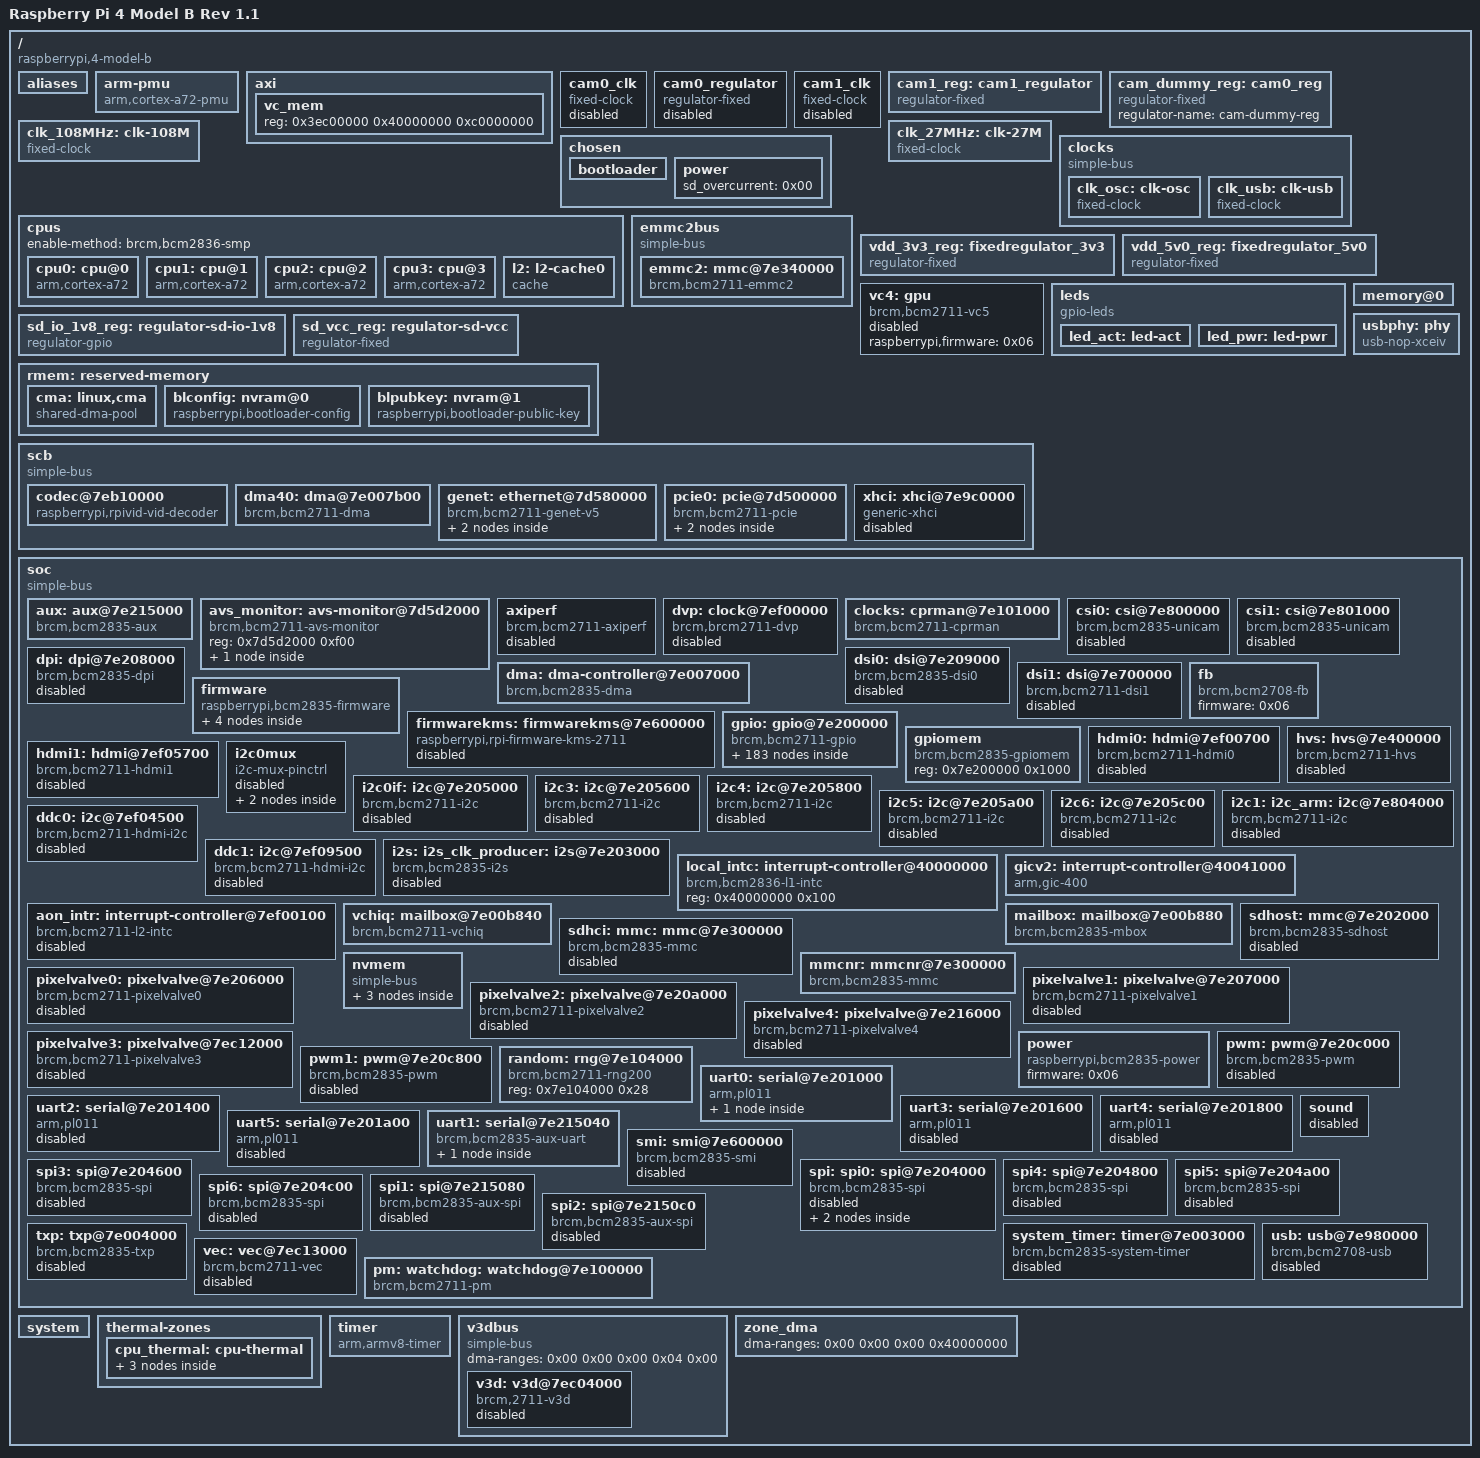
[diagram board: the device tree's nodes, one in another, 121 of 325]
/dts-v1/;

/memreserve/	0x0000000000000000 0x0000000000001000;
/ {
	#address-cells = <0x02>;
	#size-cells = <0x01>;
	compatible = "raspberrypi,4-model-b", "brcm,bcm2711";
	interrupt-parent = <0x01>;
	memreserve = <0x3b400000 0x4c00000>;
	model = "Raspberry Pi 4 Model B Rev 1.1";
	serial-number = "100000003de9072a";
	__overrides__ {
		act_led_activelow = "", "", "", "Zgpios:8";
		act_led_gpio = "", "", "", "Zgpios:4";
		act_led_trigger = "", "", "", "Zlinux,default-trigger";
		arm_freq;
		audio = "", "", "", "Tbootargs{on='snd_bcm2835.enable_headphones=1 snd_bcm2835.enable_hdmi=1',off='snd_bcm2835.enable_headphones=0 snd_bcm2835.enable_hdmi=0'}";
		axiperf = "", "", "", "Nstatus";
		bdaddr = "", "", "", "Alocal-bd-address[", "", "", "", "Afallback-bd-address?=0", "", "", "", "Blocal-bd-address[", "", "", "", "Bfallback-bd-address?=0";
		cache_line_size;
		cam0-led;
		cam0-led-ctrl;
		cam0-pwdn;
		cam0-pwdn-ctrl;
		cam0_reg = "", "", "", "Rstatus";
		cam0_reg_gpio = [00 00 00 52 67 70 69 6f 3a 34 00 00 00 00 52 67 70 69 6f 3a 30 3d 00 00 00 00 07];
		cam0_sync = "", "", "", "Qsync-gpios:0=", "", "", "", "\a", "", "", "Qsync-gpios:4", "", "", "", "Qsync-gpios:8=", "", "", "", "";
		cam0_sync_inverted = [00 00 00 51 73 79 6e 63 2d 67 70 69 6f 73 3a 30 3d 00 00 00 00 07 00 00 00 51 73 79 6e 63 2d 67 70 69 6f 73 3a 34 00 00 00 00 51 73 79 6e 63 2d 67 70 69 6f 73 3a 38 3d 00 00 00 00 01];
		cam1_reg = "", "", "", "Sstatus";
		cam1_reg_gpio = [00 00 00 53 67 70 69 6f 3a 34 00 00 00 00 53 67 70 69 6f 3a 30 3d 00 00 00 00 07];
		cam1_sync = "", "", "", "Psync-gpios:0=", "", "", "", "\a", "", "", "Psync-gpios:4", "", "", "", "Psync-gpios:8=", "", "", "", "";
		cam1_sync_inverted = [00 00 00 50 73 79 6e 63 2d 67 70 69 6f 73 3a 30 3d 00 00 00 00 07 00 00 00 50 73 79 6e 63 2d 67 70 69 6f 73 3a 34 00 00 00 00 50 73 79 6e 63 2d 67 70 69 6f 73 3a 38 3d 00 00 00 00 01];
		drm_fb0_vc4 = "", "", "", "Odrm-fb0=", "/gpu";
		drm_fb1_vc4 = "", "", "", "Odrm-fb1=", "/gpu";
		drm_fb2_vc4 = "", "", "", "Odrm-fb2=", "/gpu";
		eee = "", "", "", "Tbootargs{on='',off='genet.eee=N'}";
		eth_led0 = "", "", "", "@led-modes:0";
		eth_led1 = "", "", "", "@led-modes:4";
		hdmi = "", "", "", "Ustatus", "", "", "", "Vstatus";
		i2c = "", "", "", "Hstatus";
		i2c0 = "", "", "", "2status", "", "", "", "Gstatus";
		i2c0_baudrate = "", "", "", "2clock-frequency:0";
		i2c1 = "", "", "", "Hstatus";
		i2c1_baudrate = "", "", "", "Hclock-frequency:0";
		i2c_arm = "", "", "", "Hstatus";
		i2c_arm_baudrate = "", "", "", "Hclock-frequency:0";
		i2c_baudrate = "", "", "", "Hclock-frequency:0";
		i2c_vc = "", "", "", "2status", "", "", "", "Gstatus";
		i2c_vc_baudrate = "", "", "", "2clock-frequency:0";
		i2s = "", "", "", "Estatus";
		i2s_dma4 = <0x45 0x646d6173 0x3a303d00 0x2e 0x45 0x646d6173 0x3a383d00 0x2e>;
		krnbt = "", "", "", "Astatus";
		krnbt_baudrate = "", "", "", "Amax-speed:0", "", "", "", "Bmax-speed:0";
		nvmem_cust_rw = "", "", "", "Wrw?";
		nvmem_priv_rw = "", "", "", "Xrw?";
		pcie = "", "", "", ">status";
		pwr_led_activelow = "", "", "", "[gpios:8";
		pwr_led_gpio = "", "", "", "[gpios:4";
		pwr_led_trigger = "", "", "", "[linux,default-trigger";
		random = "", "", "", "Jstatus";
		sd = "", "", "", "Ystatus";
		sd_debug = "", "", "", "Kbrcm,debug";
		sd_force_pio = "", "", "", "Kbrcm,force-pio?";
		sd_overclock = "", "", "", "Kbrcm,overclock-50:0";
		sd_pio_limit = "", "", "", "Kbrcm,pio-limit:0";
		sd_poll_once = "", "", "", "Ynon-removable?";
		sdio_overclock = "", "", "", "Lbrcm,overclock-50:0", "", "", "", "Mbrcm,overclock-50:0";
		spi = "", "", "", "Fstatus";
		spi_dma4 = <0x46 0x646d6173 0x3a303d00 0x2e 0x46 0x646d6173 0x3a383d00 0x2e>;
		strict_gpiod = "", "", "", "Tbootargs=pinctrl_bcm2835.persist_gpio_outputs=n";
		uart0 = "", "", "", "Cstatus";
		uart1 = "", "", "", "Dstatus";
		watchdog = "", "", "", "Istatus";
	};
	__symbols__ {
		aliases = "/aliases";
		alt0 = "/soc/gpio@7e200000/alt0";
		aon_intr = "/soc/interrupt-controller@7ef00100";
		audio_pins = "/soc/gpio@7e200000/audio_pins";
		aux = "/soc/aux@7e215000";
		avs_monitor = "/soc/avs-monitor@7d5d2000";
		axiperf = "/soc/axiperf";
		blconfig = "/reserved-memory/nvram@0";
		blpubkey = "/reserved-memory/nvram@1";
		bt = "/soc/serial@7e201000/bluetooth";
		bt_pins = "/soc/gpio@7e200000/bt_pins";
		cam0_clk = "/cam0_clk";
		cam0_reg = "/cam_dummy_reg";
		cam0_regulator = "/cam0_regulator";
		cam1_clk = "/cam1_clk";
		cam1_reg = "/cam1_regulator";
		cam_dummy_reg = "/cam_dummy_reg";
		chosen = "/chosen";
		clk_108MHz = "/clk-108M";
		clk_27MHz = "/clk-27M";
		clk_osc = "/clocks/clk-osc";
		clk_usb = "/clocks/clk-usb";
		clocks = "/soc/cprman@7e101000";
		cma = "/reserved-memory/linux,cma";
		cooling_maps = "/thermal-zones/cpu-thermal/cooling-maps";
		cpu0 = "/cpus/cpu@0";
		cpu1 = "/cpus/cpu@1";
		cpu2 = "/cpus/cpu@2";
		cpu3 = "/cpus/cpu@3";
		cpu_thermal = "/thermal-zones/cpu-thermal";
		cpus = "/cpus";
		csi0 = "/soc/csi@7e800000";
		csi1 = "/soc/csi@7e801000";
		ddc0 = "/soc/i2c@7ef04500";
		ddc1 = "/soc/i2c@7ef09500";
		dma = "/soc/dma-controller@7e007000";
		dma40 = "/scb/dma@7e007b00";
		dpi = "/soc/dpi@7e208000";
		dpi_16bit_cpadhi_gpio0 = "/soc/gpio@7e200000/dpi_16bit_cpadhi_gpio0";
		dpi_16bit_cpadhi_gpio2 = "/soc/gpio@7e200000/dpi_16bit_cpadhi_gpio2";
		dpi_16bit_gpio0 = "/soc/gpio@7e200000/dpi_16bit_gpio0";
		dpi_16bit_gpio2 = "/soc/gpio@7e200000/dpi_16bit_gpio2";
		dpi_18bit_cpadhi_gpio0 = "/soc/gpio@7e200000/dpi_18bit_cpadhi_gpio0";
		dpi_18bit_cpadhi_gpio2 = "/soc/gpio@7e200000/dpi_18bit_cpadhi_gpio2";
		dpi_18bit_gpio0 = "/soc/gpio@7e200000/dpi_18bit_gpio0";
		dpi_18bit_gpio2 = "/soc/gpio@7e200000/dpi_18bit_gpio2";
		dpi_gpio0 = "/soc/gpio@7e200000/dpi-gpio0";
		dsi0 = "/soc/dsi@7e209000";
		dsi1 = "/soc/dsi@7e700000";
		dvp = "/soc/clock@7ef00000";
		emmc2 = "/emmc2bus/mmc@7e340000";
		emmc2bus = "/emmc2bus";
		emmc_gpio22 = "/soc/gpio@7e200000/emmc-gpio22";
		emmc_gpio34 = "/soc/gpio@7e200000/emmc-gpio34";
		emmc_gpio48 = "/soc/gpio@7e200000/emmc-gpio48";
		expgpio = "/soc/firmware/gpio";
		fb = "/soc/fb";
		firmware = "/soc/firmware";
		firmware_clocks = "/soc/firmware/clocks";
		firmwarekms = "/soc/firmwarekms@7e600000";
		genet = "/scb/ethernet@7d580000";
		genet_mdio = "/scb/ethernet@7d580000/mdio@e14";
		gicv2 = "/soc/interrupt-controller@40041000";
		gpclk0_gpio4 = "/soc/gpio@7e200000/gpclk0-gpio4";
		gpclk0_gpio49 = "/soc/gpio@7e200000/gpclk0-gpio49";
		gpclk1_gpio42 = "/soc/gpio@7e200000/gpclk1-gpio42";
		gpclk1_gpio44 = "/soc/gpio@7e200000/gpclk1-gpio44";
		gpclk1_gpio5 = "/soc/gpio@7e200000/gpclk1-gpio5";
		gpclk1_gpio50 = "/soc/gpio@7e200000/gpclk1-gpio50";
		gpclk2_gpio43 = "/soc/gpio@7e200000/gpclk2-gpio43";
		gpclk2_gpio51 = "/soc/gpio@7e200000/gpclk2-gpio51";
		gpclk2_gpio6 = "/soc/gpio@7e200000/gpclk2-gpio6";
		gpio = "/soc/gpio@7e200000";
		gpioout = "/soc/gpio@7e200000/gpioout";
		hdmi0 = "/soc/hdmi@7ef00700";
		hdmi1 = "/soc/hdmi@7ef05700";
		hvs = "/soc/hvs@7e400000";
		i2c0 = "/soc/i2c0mux/i2c@0";
		i2c0_gpio0 = "/soc/gpio@7e200000/i2c0if-gpio0";
		i2c0_gpio28 = "/soc/gpio@7e200000/i2c0if-gpio28";
		i2c0_gpio44 = "/soc/gpio@7e200000/i2c0if-gpio44";
		i2c0_gpio46 = "/soc/gpio@7e200000/i2c0if-gpio46";
		i2c0_pins = "/soc/gpio@7e200000/i2c0";
		i2c0if = "/soc/i2c@7e205000";
		i2c0mux = "/soc/i2c0mux";
		i2c1 = "/soc/i2c@7e804000";
		i2c1_gpio2 = "/soc/gpio@7e200000/i2c1-gpio2";
		i2c1_gpio44 = "/soc/gpio@7e200000/i2c1-gpio44";
		i2c1_gpio46 = "/soc/gpio@7e200000/i2c1-gpio46";
		i2c1_pins = "/soc/gpio@7e200000/i2c1";
		i2c3 = "/soc/i2c@7e205600";
		i2c3_gpio2 = "/soc/gpio@7e200000/i2c3-gpio2";
		i2c3_gpio4 = "/soc/gpio@7e200000/i2c3-gpio4";
		i2c3_pins = "/soc/gpio@7e200000/i2c3";
		i2c4 = "/soc/i2c@7e205800";
		i2c4_gpio6 = "/soc/gpio@7e200000/i2c4-gpio6";
		i2c4_gpio8 = "/soc/gpio@7e200000/i2c4-gpio8";
		i2c4_pins = "/soc/gpio@7e200000/i2c4";
		i2c5 = "/soc/i2c@7e205a00";
		i2c5_gpio10 = "/soc/gpio@7e200000/i2c5-gpio10";
		i2c5_gpio12 = "/soc/gpio@7e200000/i2c5-gpio12";
		i2c5_pins = "/soc/gpio@7e200000/i2c5";
		i2c6 = "/soc/i2c@7e205c00";
		i2c6_gpio0 = "/soc/gpio@7e200000/i2c6-gpio0";
		i2c6_gpio22 = "/soc/gpio@7e200000/i2c6-gpio22";
		i2c6_pins = "/soc/gpio@7e200000/i2c6";
		i2c_arm = "/soc/i2c@7e804000";
		i2c_csi_dsi = "/soc/i2c0mux/i2c@1";
		i2c_csi_dsi0 = "/soc/i2c0mux/i2c@0";
		i2c_slave_gpio8 = "/soc/gpio@7e200000/i2c-slave-gpio8";
		i2c_vc = "/soc/i2c0mux/i2c@0";
		i2s = "/soc/i2s@7e203000";
		i2s_clk_consumer = "/soc/i2s@7e203000";
		i2s_clk_producer = "/soc/i2s@7e203000";
		i2s_pins = "/soc/gpio@7e200000/i2s";
		jtag_gpio22 = "/soc/gpio@7e200000/jtag-gpio22";
		jtag_gpio48 = "/soc/gpio@7e200000/jtag-gpio48";
		l2 = "/cpus/l2-cache0";
		led_act = "/leds/led-act";
		led_pwr = "/leds/led-pwr";
		leds = "/leds";
		local_intc = "/soc/interrupt-controller@40000000";
		mailbox = "/soc/mailbox@7e00b880";
		mii_gpio28 = "/soc/gpio@7e200000/mii-gpio28";
		mii_gpio36 = "/soc/gpio@7e200000/mii-gpio36";
		minibt = "/soc/serial@7e215040/bluetooth";
		mmc = "/soc/mmc@7e300000";
		mmcnr = "/soc/mmcnr@7e300000";
		nvmem_cust = "/soc/nvmem/nvmem_cust";
		nvmem_otp = "/soc/nvmem/nvmem_otp";
		nvmem_priv = "/soc/nvmem/nvmem_priv";
		pcie0 = "/scb/pcie@7d500000";
		pcm_gpio18 = "/soc/gpio@7e200000/pcm-gpio18";
		pcm_gpio28 = "/soc/gpio@7e200000/pcm-gpio28";
		pcm_gpio50 = "/soc/gpio@7e200000/pcm-gpio50";
		phy1 = "/scb/ethernet@7d580000/mdio@e14/ethernet-phy@1";
		pixelvalve0 = "/soc/pixelvalve@7e206000";
		pixelvalve1 = "/soc/pixelvalve@7e207000";
		pixelvalve2 = "/soc/pixelvalve@7e20a000";
		pixelvalve3 = "/soc/pixelvalve@7ec12000";
		pixelvalve4 = "/soc/pixelvalve@7e216000";
		pm = "/soc/watchdog@7e100000";
		power = "/soc/power";
		pwm = "/soc/pwm@7e20c000";
		pwm0_0_gpio12 = "/soc/gpio@7e200000/pwm0-0-gpio12";
		pwm0_0_gpio18 = "/soc/gpio@7e200000/pwm0-0-gpio18";
		pwm0_0_gpio52 = "/soc/gpio@7e200000/pwm0-0-gpio52";
		pwm0_1_gpio13 = "/soc/gpio@7e200000/pwm0-1-gpio13";
		pwm0_1_gpio19 = "/soc/gpio@7e200000/pwm0-1-gpio19";
		pwm0_1_gpio45 = "/soc/gpio@7e200000/pwm0-1-gpio45";
		pwm0_1_gpio53 = "/soc/gpio@7e200000/pwm0-1-gpio53";
		pwm1 = "/soc/pwm@7e20c800";
		pwm1_0_gpio40 = "/soc/gpio@7e200000/pwm1-0-gpio40";
		pwm1_1_gpio41 = "/soc/gpio@7e200000/pwm1-1-gpio41";
		random = "/soc/rng@7e104000";
		reset = "/soc/firmware/reset";
		rgmii_gpio35 = "/soc/gpio@7e200000/rgmii-gpio35";
		rgmii_irq_gpio34 = "/soc/gpio@7e200000/rgmii-irq-gpio34";
		rgmii_irq_gpio39 = "/soc/gpio@7e200000/rgmii-irq-gpio39";
		rgmii_mdio_gpio28 = "/soc/gpio@7e200000/rgmii-mdio-gpio28";
		rgmii_mdio_gpio37 = "/soc/gpio@7e200000/rgmii-mdio-gpio37";
		rmem = "/reserved-memory";
		scb = "/scb";
		sd_io_1v8_reg = "/regulator-sd-io-1v8";
		sd_vcc_reg = "/regulator-sd-vcc";
		sdhci = "/soc/mmc@7e300000";
		sdhost = "/soc/mmc@7e202000";
		sdhost_gpio48 = "/soc/gpio@7e200000/sdhost-gpio48";
		sdio_pins = "/soc/gpio@7e200000/sdio_pins";
		smi = "/soc/smi@7e600000";
		soc = "/soc";
		sound = "/soc/sound";
		spi = "/soc/spi@7e204000";
		spi0 = "/soc/spi@7e204000";
		spi0_cs_pins = "/soc/gpio@7e200000/spi0_cs_pins";
		spi0_gpio35 = "/soc/gpio@7e200000/spi0-gpio35";
		spi0_gpio46 = "/soc/gpio@7e200000/spi0-gpio46";
		spi0_gpio7 = "/soc/gpio@7e200000/spi0-gpio7";
		spi0_pins = "/soc/gpio@7e200000/spi0_pins";
		spi1 = "/soc/spi@7e215080";
		spi1_gpio16 = "/soc/gpio@7e200000/spi1-gpio16";
		spi2 = "/soc/spi@7e2150c0";
		spi2_gpio40 = "/soc/gpio@7e200000/spi2-gpio40";
		spi2_gpio46 = "/soc/gpio@7e200000/spi2-gpio46";
		spi3 = "/soc/spi@7e204600";
		spi3_cs_pins = "/soc/gpio@7e200000/spi3_cs_pins";
		spi3_gpio0 = "/soc/gpio@7e200000/spi3-gpio0";
		spi3_pins = "/soc/gpio@7e200000/spi3_pins";
		spi4 = "/soc/spi@7e204800";
		spi4_cs_pins = "/soc/gpio@7e200000/spi4_cs_pins";
		spi4_gpio4 = "/soc/gpio@7e200000/spi4-gpio4";
		spi4_pins = "/soc/gpio@7e200000/spi4_pins";
		spi5 = "/soc/spi@7e204a00";
		spi5_cs_pins = "/soc/gpio@7e200000/spi5_cs_pins";
		spi5_gpio12 = "/soc/gpio@7e200000/spi5-gpio12";
		spi5_pins = "/soc/gpio@7e200000/spi5_pins";
		spi6 = "/soc/spi@7e204c00";
		spi6_cs_pins = "/soc/gpio@7e200000/spi6_cs_pins";
		spi6_gpio18 = "/soc/gpio@7e200000/spi6-gpio18";
		spi6_pins = "/soc/gpio@7e200000/spi6_pins";
		spidev0 = "/soc/spi@7e204000/spidev@0";
		spidev1 = "/soc/spi@7e204000/spidev@1";
		system_timer = "/soc/timer@7e003000";
		thermal = "/soc/avs-monitor@7d5d2000/thermal";
		thermal_trips = "/thermal-zones/cpu-thermal/trips";
		txp = "/soc/txp@7e004000";
		uart0 = "/soc/serial@7e201000";
		uart0_ctsrts_gpio16 = "/soc/gpio@7e200000/uart0-ctsrts-gpio16";
		uart0_ctsrts_gpio30 = "/soc/gpio@7e200000/uart0-ctsrts-gpio30";
		uart0_ctsrts_gpio38 = "/soc/gpio@7e200000/uart0-ctsrts-gpio38";
		uart0_gpio14 = "/soc/gpio@7e200000/uart0-gpio14";
		uart0_gpio32 = "/soc/gpio@7e200000/uart0-gpio32";
		uart0_gpio36 = "/soc/gpio@7e200000/uart0-gpio36";
		uart0_pins = "/soc/gpio@7e200000/uart0_pins";
		uart1 = "/soc/serial@7e215040";
		uart1_bt_pins = "/soc/gpio@7e200000/uart1_bt_pins";
		uart1_ctsrts_gpio16 = "/soc/gpio@7e200000/uart1-ctsrts-gpio16";
		uart1_ctsrts_gpio30 = "/soc/gpio@7e200000/uart1-ctsrts-gpio30";
		uart1_ctsrts_gpio42 = "/soc/gpio@7e200000/uart1-ctsrts-gpio42";
		uart1_gpio14 = "/soc/gpio@7e200000/uart1-gpio14";
		uart1_gpio32 = "/soc/gpio@7e200000/uart1-gpio32";
		uart1_gpio40 = "/soc/gpio@7e200000/uart1-gpio40";
		uart1_pins = "/soc/gpio@7e200000/uart1_pins";
		uart2 = "/soc/serial@7e201400";
		uart2_ctsrts_gpio2 = "/soc/gpio@7e200000/uart2-ctsrts-gpio2";
		uart2_gpio0 = "/soc/gpio@7e200000/uart2-gpio0";
		uart2_pins = "/soc/gpio@7e200000/uart2_pins";
		uart3 = "/soc/serial@7e201600";
		uart3_ctsrts_gpio6 = "/soc/gpio@7e200000/uart3-ctsrts-gpio6";
		uart3_gpio4 = "/soc/gpio@7e200000/uart3-gpio4";
		uart3_pins = "/soc/gpio@7e200000/uart3_pins";
		uart4 = "/soc/serial@7e201800";
		uart4_ctsrts_gpio10 = "/soc/gpio@7e200000/uart4-ctsrts-gpio10";
		uart4_gpio8 = "/soc/gpio@7e200000/uart4-gpio8";
		uart4_pins = "/soc/gpio@7e200000/uart4_pins";
		uart5 = "/soc/serial@7e201a00";
		uart5_ctsrts_gpio14 = "/soc/gpio@7e200000/uart5-ctsrts-gpio14";
		uart5_gpio12 = "/soc/gpio@7e200000/uart5-gpio12";
		uart5_pins = "/soc/gpio@7e200000/uart5_pins";
		usb = "/soc/usb@7e980000";
		usbphy = "/phy";
		v3d = "/v3dbus/v3d@7ec04000";
		v3dbus = "/v3dbus";
		vc4 = "/gpu";
		vchiq = "/soc/mailbox@7e00b840";
		vcio = "/soc/firmware/vcio";
		vdd_3v3_reg = "/fixedregulator_3v3";
		vdd_5v0_reg = "/fixedregulator_5v0";
		vec = "/soc/vec@7ec13000";
		watchdog = "/soc/watchdog@7e100000";
		xhci = "/scb/xhci@7e9c0000";
	};
	aliases: aliases {
		aux = "/soc/aux@7e215000";
		axiperf = "/soc/axiperf";
		blconfig = "/reserved-memory/nvram@0";
		blpubkey = "/reserved-memory/nvram@1";
		bluetooth = "/soc/serial@7e201000/bluetooth";
		dma = "/soc/dma-controller@7e007000";
		emmc2bus = "/emmc2bus";
		ethernet0 = "/scb/ethernet@7d580000";
		fb = "/soc/fb";
		gpio = "/soc/gpio@7e200000";
		i2c = "/soc/i2c@7e804000";
		i2c0 = "/soc/i2c0mux/i2c@0";
		i2c1 = "/soc/i2c@7e804000";
		i2c10 = "/soc/i2c0mux/i2c@1";
		i2c20 = "/soc/i2c@7ef04500";
		i2c21 = "/soc/i2c@7ef09500";
		i2c3 = "/soc/i2c@7e205600";
		i2c4 = "/soc/i2c@7e205800";
		i2c5 = "/soc/i2c@7e205a00";
		i2c6 = "/soc/i2c@7e205c00";
		i2s = "/soc/i2s@7e203000";
		leds = "/leds";
		mailbox = "/soc/mailbox@7e00b880";
		mmc = "/soc/mmc@7e300000";
		mmc0 = "/emmc2bus/mmc@7e340000";
		mmc1 = "/soc/mmcnr@7e300000";
		mmc2 = "/soc/mmc@7e202000";
		pcie0 = "/scb/pcie@7d500000";
		phandle = <0x4f>;
		random = "/soc/rng@7e104000";
		sdhost = "/soc/mmc@7e202000";
		serial0 = "/soc/serial@7e215040";
		serial1 = "/soc/serial@7e201000";
		serial2 = "/soc/serial@7e201400";
		serial3 = "/soc/serial@7e201600";
		serial4 = "/soc/serial@7e201800";
		serial5 = "/soc/serial@7e201a00";
		soc = "/soc";
		sound = "/soc/sound";
		spi0 = "/soc/spi@7e204000";
		spi1 = "/soc/spi@7e215080";
		spi2 = "/soc/spi@7e2150c0";
		spi3 = "/soc/spi@7e204600";
		spi4 = "/soc/spi@7e204800";
		spi5 = "/soc/spi@7e204a00";
		spi6 = "/soc/spi@7e204c00";
		thermal = "/soc/avs-monitor@7d5d2000/thermal";
		uart0 = "/soc/serial@7e201000";
		uart1 = "/soc/serial@7e215040";
		uart2 = "/soc/serial@7e201400";
		uart3 = "/soc/serial@7e201600";
		uart4 = "/soc/serial@7e201800";
		uart5 = "/soc/serial@7e201a00";
		usb = "/soc/usb@7e980000";
		watchdog = "/soc/watchdog@7e100000";
	};
	arm-pmu {
		compatible = "arm,cortex-a72-pmu", "arm,armv8-pmuv3", "arm,cortex-a7-pmu";
		interrupt-affinity = <0x39 0x3a 0x3b 0x3c>;
		interrupts = <0x00 0x10 0x04 0x00 0x11 0x04 0x00 0x12 0x04 0x00 0x13 0x04>;
	};
	axi {
		vc_mem {
			reg = <0x3ec00000 0x40000000 0xc0000000>;
		};
	};
	cam0_clk: cam0_clk {
		#clock-cells = <0x00>;
		compatible = "fixed-clock";
		phandle = <0xed>;
		status = "disabled";
	};
	cam0_regulator: cam0_regulator {
		compatible = "regulator-fixed";
		enable-active-high;
		phandle = <0xec>;
		regulator-name = "cam0-reg";
		status = "disabled";
	};
	cam1_clk: cam1_clk {
		#clock-cells = <0x00>;
		compatible = "fixed-clock";
		phandle = <0xeb>;
		status = "disabled";
	};
	cam1_reg: cam1_regulator {
		compatible = "regulator-fixed";
		enable-active-high;
		gpio = <0x0b 0x05 0x00>;
		phandle = <0x53>;
		regulator-name = "cam1-reg";
		status = "okay";
	};
	cam_dummy_reg: cam0_reg: cam_dummy_reg {
		compatible = "regulator-fixed";
		phandle = <0x52>;
		regulator-name = "cam-dummy-reg";
		status = "okay";
	};
	chosen: chosen {
		bootargs = "coherent_pool=1M 8250.nr_uarts=1 snd_bcm2835.enable_headphones=0 cgroup_disable=memory numa_policy=interleave bcm2708_fb.fbwidth=0 bcm2708_fb.fbheight=0 bcm2708_fb.fbswap=1 numa=fake=2 system_heap.max_order=0 iommu_dma_numa_policy=interleave smsc95xx.macaddr=DC:A6:32:42:AA:0B vc_mem.mem_base=0x3ec00000 vc_mem.mem_size=0x40000000  console=ttyAMA0,115200 kgdboc=ttyAMA0,115200 console=tty1 root=/dev/mmcblk0p2 rootfstype=ext4 rootwait";
		kaslr-seed = <0xbb563d26 0x86358a25>;
		log = <0x3ff80000 0x7ffe0>;
		os_prefix = [00];
		overlay_prefix = "overlays/";
		phandle = <0x54>;
		rng-seed = <0x9971a6e6 0x8466f46 0x72bf2d70 0xd8c0ac17 0x7b4b04eb 0x1f7221db 0xd7a8573a 0xa4d811be 0x6458ed7a 0xfa5b4908 0x6818384f 0x8538940f 0x1e90062c 0xdd7fbb8 0xb65e083f 0xc46f6a48>;
		rpi-boardrev-ext = <0x00>;
		rpi-machine-id = [32 66 35 63 31 66 37 62 34 64 32 63 32 66 62 36 35 64 65 32 37 34 38 36 38 66 31 61 35 36 35 63 0a];
		rpi-min-boot-ver = <0x00>;
		rpi-sdram-size-gbit = <0x20>;
		rpi-serial64 = "404172c63de9072a";
		stdout-path = "serial0:115200n8";
		user-warnings = [46 61 69 6c 65 64 20 74 6f 20 6f 70 65 6e 20 63 6f 6d 6d 61 6e 64 20 6c 69 6e 65 20 66 69 6c 65 20 27 63 6d 64 6c 69 6e 65 2e 74 78 74 27 0a];
		bootloader {
			boot-mode = <0x01>;
			build-timestamp = <0x6a0a134e>;
			capabilities = <0x7f>;
			partition = <0x01>;
			rsts = <0x1000>;
			tryboot = <0x00>;
			update-timestamp = <0x6a95e58c>;
			version = "224877da90f82a72dbcc9db10bcf059259f54680";
		};
		power {
			sd_overcurrent = <0x00>;
		};
	};
	clk_108MHz: clk-108M {
		#clock-cells = <0x00>;
		clock-frequency = <0x66ff300>;
		clock-output-names = "108MHz-clock";
		compatible = "fixed-clock";
		phandle = <0x2a>;
	};
	clk_27MHz: clk-27M {
		#clock-cells = <0x00>;
		clock-frequency = <0x19bfcc0>;
		clock-output-names = "27MHz-clock";
		compatible = "fixed-clock";
		phandle = <0x2f>;
	};
	clocks {
		#address-cells = <0x01>;
		#size-cells = <0x00>;
		compatible = "simple-bus";
		clk_osc: clk-osc {
			#clock-cells = <0x00>;
			clock-frequency = <0x337f980>;
			clock-output-names = "osc";
			compatible = "fixed-clock";
			phandle = <0x03>;
		};
		clk_usb: clk-usb {
			#clock-cells = <0x00>;
			clock-frequency = <0x1c9c3800>;
			clock-output-names = "otg";
			compatible = "fixed-clock";
			phandle = <0x16>;
		};
	};
	cpus: cpus {
		#address-cells = <0x01>;
		#size-cells = <0x00>;
		enable-method = "brcm,bcm2836-smp";
		phandle = <0xe6>;
		cpu0: cpu@0 {
			compatible = "arm,cortex-a72";
			cpu-release-addr = <0x00 0xd8>;
			d-cache-line-size = <0x40>;
			d-cache-sets = <0x100>;
			d-cache-size = <0x8000>;
			device_type = "cpu";
			enable-method = "spin-table";
			i-cache-line-size = <0x40>;
			i-cache-sets = <0x100>;
			i-cache-size = <0xc000>;
			next-level-cache = <0x3d>;
			phandle = <0x39>;
			reg = <0x00>;
		};
		cpu1: cpu@1 {
			compatible = "arm,cortex-a72";
			cpu-release-addr = <0x00 0xe0>;
			d-cache-line-size = <0x40>;
			d-cache-sets = <0x100>;
			d-cache-size = <0x8000>;
			device_type = "cpu";
			enable-method = "spin-table";
			i-cache-line-size = <0x40>;
			i-cache-sets = <0x100>;
			i-cache-size = <0xc000>;
			next-level-cache = <0x3d>;
			phandle = <0x3a>;
			reg = <0x01>;
		};
		cpu2: cpu@2 {
			compatible = "arm,cortex-a72";
			cpu-release-addr = <0x00 0xe8>;
			d-cache-line-size = <0x40>;
			d-cache-sets = <0x100>;
			d-cache-size = <0x8000>;
			device_type = "cpu";
			enable-method = "spin-table";
			i-cache-line-size = <0x40>;
			i-cache-sets = <0x100>;
			i-cache-size = <0xc000>;
			next-level-cache = <0x3d>;
			phandle = <0x3b>;
			reg = <0x02>;
		};
		cpu3: cpu@3 {
			compatible = "arm,cortex-a72";
			cpu-release-addr = <0x00 0xf0>;
			d-cache-line-size = <0x40>;
			d-cache-sets = <0x100>;
			d-cache-size = <0x8000>;
			device_type = "cpu";
			enable-method = "spin-table";
			i-cache-line-size = <0x40>;
			i-cache-sets = <0x100>;
			i-cache-size = <0xc000>;
			next-level-cache = <0x3d>;
			phandle = <0x3c>;
			reg = <0x03>;
		};
		l2: l2-cache0 {
			cache-level = <0x02>;
			cache-line-size = <0x40>;
			cache-sets = <0x400>;
			cache-size = <0x100000>;
			cache-unified;
			compatible = "cache";
			phandle = <0x3d>;
		};
	};
	emmc2bus: emmc2bus {
		#address-cells = <0x02>;
		#size-cells = <0x01>;
		compatible = "simple-bus";
		dma-ranges = <0x00 0xc0000000 0x00 0x00 0x40000000>;
		phandle = <0xe5>;
		ranges = <0x00 0x7e000000 0x00 0xfe000000 0x1800000>;
		emmc2: mmc@7e340000 {
			broken-cd;
			clocks = <0x08 0x33>;
			compatible = "brcm,bcm2711-emmc2";
			interrupts = <0x00 0x7e 0x04>;
			mmc-ddr-3_3v;
			phandle = <0x59>;
			reg = <0x00 0x7e340000 0x100>;
			status = "okay";
			vmmc-supply = <0x38>;
			vqmmc-supply = <0x37>;
		};
	};
	vdd_3v3_reg: fixedregulator_3v3 {
		compatible = "regulator-fixed";
		phandle = <0xef>;
		regulator-always-on;
		regulator-max-microvolt = <0x325aa0>;
		regulator-min-microvolt = <0x325aa0>;
		regulator-name = "3v3";
	};
	vdd_5v0_reg: fixedregulator_5v0 {
		compatible = "regulator-fixed";
		phandle = <0xf0>;
		regulator-always-on;
		regulator-max-microvolt = <0x4c4b40>;
		regulator-min-microvolt = <0x4c4b40>;
		regulator-name = "5v0";
	};
	vc4: gpu {
		compatible = "brcm,bcm2711-vc5";
		phandle = <0xe4>;
		raspberrypi,firmware = <0x06>;
		status = "disabled";
	};
	leds: leds {
		compatible = "gpio-leds";
		phandle = <0xee>;
		led_act: led-act {
			default-state = "off";
			gpios = <0x07 0x2a 0x00>;
			label = "ACT";
			linux,default-trigger = "mmc0";
			phandle = <0x5a>;
		};
		led_pwr: led-pwr {
			default-state = "off";
			gpios = <0x0b 0x02 0x01>;
			label = "PWR";
			linux,default-trigger = "default-on";
			phandle = <0x5b>;
		};
	};
	memory@0 {
		device_type = "memory";
		reg = <0x00 0x00 0x3b400000 0x00 0x40000000 0xbc000000>;
	};
	usbphy: phy {
		#phy-cells = <0x00>;
		compatible = "usb-nop-xceiv";
		phandle = <0x17>;
	};
	sd_io_1v8_reg: regulator-sd-io-1v8 {
		compatible = "regulator-gpio";
		gpios = <0x0b 0x04 0x00>;
		phandle = <0x37>;
		regulator-always-on;
		regulator-boot-on;
		regulator-max-microvolt = <0x325aa0>;
		regulator-min-microvolt = <0x1b7740>;
		regulator-name = "vdd-sd-io";
		regulator-settling-time-us = <0x1388>;
		states = <0x1b7740 0x01 0x325aa0 0x00>;
		status = "okay";
	};
	sd_vcc_reg: regulator-sd-vcc {
		compatible = "regulator-fixed";
		enable-active-high;
		gpio = <0x0b 0x06 0x00>;
		phandle = <0x38>;
		regulator-boot-on;
		regulator-max-microvolt = <0x325aa0>;
		regulator-min-microvolt = <0x325aa0>;
		regulator-name = "vcc-sd";
	};
	rmem: reserved-memory {
		#address-cells = <0x02>;
		#size-cells = <0x01>;
		phandle = <0x5c>;
		ranges;
		cma: linux,cma {
			alloc-ranges = <0x00 0x00 0x30000000>;
			compatible = "shared-dma-pool";
			linux,cma-default;
			phandle = <0x5d>;
			reusable;
			size = <0x4000000>;
		};
		blconfig: nvram@0 {
			#address-cells = <0x01>;
			#size-cells = <0x01>;
			compatible = "raspberrypi,bootloader-config", "nvmem-rmem";
			no-map;
			phandle = <0x5e>;
			reg = <0x00 0x3ef735c0 0x3ec>;
			status = "okay";
		};
		blpubkey: nvram@1 {
			#address-cells = <0x01>;
			#size-cells = <0x01>;
			compatible = "raspberrypi,bootloader-public-key", "nvmem-rmem";
			no-map;
			phandle = <0x5f>;
			reg = <0x00 0x3ef73380 0x200>;
			status = "okay";
		};
	};
	scb: scb {
		#address-cells = <0x02>;
		#size-cells = <0x02>;
		compatible = "simple-bus";
		dma-ranges = <0x04 0x7c000000 0x00 0xfc000000 0x00 0x3800000 0x00 0x00 0x00 0x00 0x04 0x00>;
		phandle = <0xe7>;
		ranges = <0x00 0x7c000000 0x00 0xfc000000 0x00 0x3800000 0x00 0x40000000 0x00 0xff800000 0x00 0x800000 0x06 0x00 0x06 0x00 0x00 0x80000000 0x00 0x00 0x00 0x00 0x00 0xfc000000>;
		codec@7eb10000 {
			clock-names = "hevc";
			clocks = <0x14 0x0b>;
			compatible = "raspberrypi,rpivid-vid-decoder";
			interrupts = <0x00 0x62 0x04>;
			reg = <0x00 0x7eb10000 0x00 0x1000 0x00 0x7eb00000 0x00 0x10000>;
			reg-names = "intc", "hevc";
		};
		dma40: dma@7e007b00 {
			#dma-cells = <0x01>;
			brcm,dma-channel-mask = <0x3000>;
			compatible = "brcm,bcm2711-dma";
			dma-channel-mask = <0x3000>;
			interrupt-names = "dma11", "dma12", "dma13", "dma14";
			interrupts = <0x00 0x59 0x04 0x00 0x5a 0x04 0x00 0x5b 0x04 0x00 0x5c 0x04>;
			phandle = <0x2e>;
			reg = <0x00 0x7e007b00 0x00 0x400>;
		};
		genet: ethernet@7d580000 {
			#address-cells = <0x01>;
			#size-cells = <0x01>;
			compatible = "brcm,bcm2711-genet-v5";
			interrupts = <0x00 0x9d 0x04 0x00 0x9e 0x04>;
			local-mac-address = [dc a6 32 42 aa 0b];
			phandle = <0xe8>;
			phy-handle = <0x40>;
			phy-mode = "rgmii-rxid";
			reg = <0x00 0x7d580000 0x00 0x10000>;
			status = "okay";
			genet_mdio: mdio@e14 {
				#address-cells = <0x01>;
				#size-cells = <0x00>;
				compatible = "brcm,genet-mdio-v5";
				phandle = <0xe9>;
				reg = <0xe14 0x08>;
				reg-names = "mdio";
				phy1: ethernet-phy@1 {
					led-modes = <0x00 0x08>;
					phandle = <0x40>;
					reg = <0x01>;
				};
			};
		};
		pcie0: pcie@7d500000 {
			#address-cells = <0x03>;
			#interrupt-cells = <0x01>;
			#size-cells = <0x02>;
			brcm,enable-ssc;
			compatible = "brcm,bcm2711-pcie";
			device_type = "pci";
			dma-ranges = <0x2000000 0x04 0x00 0x00 0x00 0x00 0xc0000000>;
			interrupt-map = <0x00 0x00 0x00 0x01 0x01 0x00 0x8f 0x04 0x00 0x00 0x00 0x02 0x01 0x00 0x90 0x04 0x00 0x00 0x00 0x03 0x01 0x00 0x91 0x04 0x00 0x00 0x00 0x04 0x01 0x00 0x92 0x04>;
			interrupt-map-mask = <0x00 0x00 0x00 0x07>;
			interrupt-names = "pcie", "msi";
			interrupts = <0x00 0x93 0x04 0x00 0x94 0x04>;
			msi-controller;
			msi-parent = <0x3e>;
			phandle = <0x3e>;
			ranges = <0x2000000 0x00 0x80000000 0x06 0x00 0x00 0x80000000>;
			reg = <0x00 0x7d500000 0x00 0x9310>;
			pci@0,0 {
				#address-cells = <0x03>;
				#size-cells = <0x02>;
				device_type = "pci";
				ranges;
				reg = <0x00 0x00 0x00 0x00 0x00>;
				usb@0,0 {
					reg = <0x00 0x00 0x00 0x00 0x00>;
					resets = <0x3f 0x00>;
				};
			};
		};
		xhci: xhci@7e9c0000 {
			compatible = "generic-xhci";
			interrupts = <0x00 0xb0 0x04>;
			phandle = <0xea>;
			power-domains = <0x10 0x06>;
			reg = <0x00 0x7e9c0000 0x00 0x100000>;
			status = "disabled";
		};
	};
	soc: soc {
		#address-cells = <0x01>;
		#size-cells = <0x01>;
		compatible = "simple-bus";
		dma-ranges = <0xc0000000 0x00 0x00 0x40000000 0x7c000000 0x00 0xfc000000 0x3800000>;
		phandle = <0x63>;
		ranges = <0x7e000000 0x00 0xfe000000 0x1800000 0x7c000000 0x00 0xfc000000 0x2000000 0x40000000 0x00 0xff800000 0x800000>;
		aux: aux@7e215000 {
			#clock-cells = <0x01>;
			clocks = <0x08 0x14>;
			compatible = "brcm,bcm2835-aux";
			phandle = <0x11>;
			reg = <0x7e215000 0x08>;
		};
		avs_monitor: avs-monitor@7d5d2000 {
			compatible = "brcm,bcm2711-avs-monitor", "syscon", "simple-mfd";
			phandle = <0xc7>;
			reg = <0x7d5d2000 0xf00>;
			thermal: thermal {
				#thermal-sensor-cells = <0x00>;
				compatible = "brcm,bcm2711-thermal";
				phandle = <0x02>;
			};
		};
		axiperf: axiperf {
			compatible = "brcm,bcm2711-axiperf";
			firmware = <0x06>;
			phandle = <0x4e>;
			reg = <0x7e009800 0x100 0x7ee08000 0x100>;
			status = "disabled";
		};
		dvp: clock@7ef00000 {
			#clock-cells = <0x01>;
			#reset-cells = <0x01>;
			clocks = <0x2a>;
			compatible = "brcm,brcm2711-dvp";
			phandle = <0x2b>;
			reg = <0x7ef00000 0x10>;
			status = "disabled";
		};
		clocks: cprman@7e101000 {
			#clock-cells = <0x01>;
			clocks = <0x03 0x04 0x00 0x04 0x01 0x04 0x02 0x05 0x00 0x05 0x01 0x05 0x02>;
			compatible = "brcm,bcm2711-cprman";
			firmware = <0x06>;
			phandle = <0x08>;
			reg = <0x7e101000 0x2000>;
		};
		csi0: csi@7e800000 {
			#address-cells = <0x01>;
			#clock-cells = <0x01>;
			#size-cells = <0x00>;
			clock-names = "lp", "vpu";
			clocks = <0x08 0x2d 0x14 0x04>;
			compatible = "brcm,bcm2835-unicam";
			interrupts = <0x00 0x66 0x04>;
			phandle = <0x51>;
			power-domains = <0x10 0x0c>;
			reg = <0x7e800000 0x800 0x7e802000 0x04>;
			status = "disabled";
		};
		csi1: csi@7e801000 {
			#address-cells = <0x01>;
			#clock-cells = <0x01>;
			#size-cells = <0x00>;
			brcm,num-data-lanes = <0x02>;
			clock-names = "lp", "vpu";
			clocks = <0x08 0x2e 0x14 0x04>;
			compatible = "brcm,bcm2835-unicam";
			interrupts = <0x00 0x67 0x04>;
			phandle = <0x50>;
			power-domains = <0x10 0x0d>;
			reg = <0x7e801000 0x800 0x7e802004 0x04>;
			status = "disabled";
		};
		dma: dma-controller@7e007000 {
			#dma-cells = <0x01>;
			brcm,dma-channel-mask = <0x7f5>;
			compatible = "brcm,bcm2835-dma";
			interrupt-names = "dma0", "dma1", "dma2", "dma3", "dma4", "dma5", "dma6", "dma7", "dma8", "dma9", "dma10";
			interrupts = <0x00 0x50 0x04 0x00 0x51 0x04 0x00 0x52 0x04 0x00 0x53 0x04 0x00 0x54 0x04 0x00 0x55 0x04 0x00 0x56 0x04 0x00 0x57 0x04 0x00 0x57 0x04 0x00 0x58 0x04 0x00 0x58 0x04>;
			phandle = <0x0c>;
			reg = <0x7e007000 0xb00>;
		};
		dpi: dpi@7e208000 {
			clock-names = "core", "pixel";
			clocks = <0x08 0x14 0x08 0x2c>;
			compatible = "brcm,bcm2835-dpi";
			phandle = <0xc0>;
			reg = <0x7e208000 0x8c>;
			status = "disabled";
		};
		dsi0: dsi@7e209000 {
			#address-cells = <0x01>;
			#clock-cells = <0x01>;
			#size-cells = <0x00>;
			clock-names = "phy", "escape", "pixel";
			clock-output-names = "dsi0_byte", "dsi0_ddr2", "dsi0_ddr";
			clocks = <0x08 0x22 0x08 0x2f 0x08 0x31>;
			compatible = "brcm,bcm2835-dsi0";
			interrupts = <0x00 0x64 0x04>;
			phandle = <0x04>;
			power-domains = <0x10 0x11>;
			reg = <0x7e209000 0x78>;
			status = "disabled";
		};
		dsi1: dsi@7e700000 {
			#address-cells = <0x01>;
			#clock-cells = <0x01>;
			#size-cells = <0x00>;
			clock-names = "phy", "escape", "pixel";
			clock-output-names = "dsi1_byte", "dsi1_ddr2", "dsi1_ddr";
			clocks = <0x08 0x23 0x08 0x30 0x08 0x32>;
			compatible = "brcm,bcm2711-dsi1";
			interrupts = <0x00 0x6c 0x04>;
			phandle = <0x05>;
			power-domains = <0x10 0x12>;
			reg = <0x7e700000 0x8c>;
			status = "disabled";
		};
		fb: fb {
			compatible = "brcm,bcm2708-fb";
			firmware = <0x06>;
			phandle = <0xe1>;
			status = "okay";
		};
		firmware: firmware {
			#address-cells = <0x01>;
			#size-cells = <0x01>;
			compatible = "raspberrypi,bcm2835-firmware", "simple-mfd";
			dma-ranges;
			mboxes = <0x35>;
			phandle = <0x06>;
			firmware_clocks: clocks {
				#clock-cells = <0x01>;
				compatible = "raspberrypi,firmware-clocks";
				phandle = <0x14>;
			};
			expgpio: gpio {
				#gpio-cells = <0x02>;
				compatible = "raspberrypi,firmware-gpio";
				gpio-controller;
				gpio-line-names = "BT_ON", "WL_ON", "PWR_LED_OFF", "GLOBAL_RESET", "VDD_SD_IO_SEL", "CAM_GPIO", "SD_PWR_ON", "SD_OC_N";
				phandle = <0x0b>;
				status = "okay";
			};
			reset: reset {
				#reset-cells = <0x01>;
				compatible = "raspberrypi,firmware-reset";
				phandle = <0x3f>;
			};
			vcio: vcio {
				compatible = "raspberrypi,vcio";
				phandle = <0xdf>;
			};
		};
		firmwarekms: firmwarekms@7e600000 {
			brcm,firmware = <0x06>;
			compatible = "raspberrypi,rpi-firmware-kms-2711";
			interrupts = <0x00 0x70 0x04>;
			phandle = <0xdb>;
			reg = <0x7e600000 0x100>;
			status = "disabled";
		};
		gpio: gpio@7e200000 {
			#gpio-cells = <0x02>;
			#interrupt-cells = <0x02>;
			compatible = "brcm,bcm2711-gpio";
			gpio-controller;
			gpio-line-names = "ID_SDA", "ID_SCL", "GPIO2", "GPIO3", "GPIO4", "GPIO5", "GPIO6", "GPIO7", "GPIO8", "GPIO9", "GPIO10", "GPIO11", "GPIO12", "GPIO13", "GPIO14", "GPIO15", "GPIO16", "GPIO17", "GPIO18", "GPIO19", "GPIO20", "GPIO21", "GPIO22", "GPIO23", "GPIO24", "GPIO25", "GPIO26", "GPIO27", "RGMII_MDIO", "RGMIO_MDC", "CTS0", "RTS0", "TXD0", "RXD0", "SD1_CLK", "SD1_CMD", "SD1_DATA0", "SD1_DATA1", "SD1_DATA2", "SD1_DATA3", "PWM0_MISO", "PWM1_MOSI", "STATUS_LED_G_CLK", "SPIFLASH_CE_N", "SDA0", "SCL0", "RGMII_RXCLK", "RGMII_RXCTL", "RGMII_RXD0", "RGMII_RXD1", "RGMII_RXD2", "RGMII_RXD3", "RGMII_TXCLK", "RGMII_TXCTL", "RGMII_TXD0", "RGMII_TXD1", "RGMII_TXD2", "RGMII_TXD3";
			gpio-ranges = <0x07 0x00 0x00 0x3a>;
			interrupt-controller;
			interrupts = <0x00 0x71 0x04 0x00 0x72 0x04>;
			phandle = <0x07>;
			reg = <0x7e200000 0xb4>;
			alt0: alt0 {
				brcm,function = <0x04>;
				brcm,pins = <0x04 0x05 0x07 0x08 0x09 0x0a 0x0b>;
				phandle = <0xbb>;
			};
			audio_pins: audio_pins {
				brcm,function = <0x04>;
				brcm,pins = <0x28 0x29>;
				brcm,pull = <0x00>;
				phandle = <0x36>;
			};
			bt_pins: bt_pins {
				brcm,function = <0x00>;
				brcm,pins = "-";
				brcm,pull = <0x02>;
				phandle = <0x0a>;
			};
			dpi_gpio0: dpi-gpio0 {
				brcm,function = <0x06>;
				brcm,pins = <0x00 0x01 0x02 0x03 0x04 0x05 0x06 0x07 0x08 0x09 0x0a 0x0b 0x0c 0x0d 0x0e 0x0f 0x10 0x11 0x12 0x13 0x14 0x15 0x16 0x17 0x18 0x19 0x1a 0x1b>;
				phandle = <0x66>;
			};
			dpi_16bit_cpadhi_gpio0: dpi_16bit_cpadhi_gpio0 {
				brcm,function = <0x06>;
				brcm,pins = <0x00 0x01 0x02 0x03 0x04 0x05 0x06 0x07 0x08 0x0c 0x0d 0x0e 0x0f 0x10 0x11 0x14 0x15 0x16 0x17 0x18>;
				phandle = <0xb8>;
			};
			dpi_16bit_cpadhi_gpio2: dpi_16bit_cpadhi_gpio2 {
				brcm,function = <0x06>;
				brcm,pins = <0x02 0x03 0x04 0x05 0x06 0x07 0x08 0x0c 0x0d 0x0e 0x0f 0x10 0x11 0x14 0x15 0x16 0x17 0x18>;
				phandle = <0xb9>;
			};
			dpi_16bit_gpio0: dpi_16bit_gpio0 {
				brcm,function = <0x06>;
				brcm,pins = <0x00 0x01 0x02 0x03 0x04 0x05 0x06 0x07 0x08 0x09 0x0a 0x0b 0x0c 0x0d 0x0e 0x0f 0x10 0x11 0x12 0x13>;
				phandle = <0xb6>;
			};
			dpi_16bit_gpio2: dpi_16bit_gpio2 {
				brcm,function = <0x06>;
				brcm,pins = <0x02 0x03 0x04 0x05 0x06 0x07 0x08 0x09 0x0a 0x0b 0x0c 0x0d 0x0e 0x0f 0x10 0x11 0x12 0x13>;
				phandle = <0xb7>;
			};
			dpi_18bit_cpadhi_gpio0: dpi_18bit_cpadhi_gpio0 {
				brcm,function = <0x06>;
				brcm,pins = <0x00 0x01 0x02 0x03 0x04 0x05 0x06 0x07 0x08 0x09 0x0c 0x0d 0x0e 0x0f 0x10 0x11 0x14 0x15 0x16 0x17 0x18 0x19>;
				brcm,pull = <0x00>;
				phandle = <0xb2>;
			};
			dpi_18bit_cpadhi_gpio2: dpi_18bit_cpadhi_gpio2 {
				brcm,function = <0x06>;
				brcm,pins = <0x02 0x03 0x04 0x05 0x06 0x07 0x08 0x09 0x0c 0x0d 0x0e 0x0f 0x10 0x11 0x14 0x15 0x16 0x17 0x18 0x19>;
				phandle = <0xb3>;
			};
			dpi_18bit_gpio0: dpi_18bit_gpio0 {
				brcm,function = <0x06>;
				brcm,pins = <0x00 0x01 0x02 0x03 0x04 0x05 0x06 0x07 0x08 0x09 0x0a 0x0b 0x0c 0x0d 0x0e 0x0f 0x10 0x11 0x12 0x13 0x14 0x15>;
				phandle = <0xb4>;
			};
			dpi_18bit_gpio2: dpi_18bit_gpio2 {
				brcm,function = <0x06>;
				brcm,pins = <0x02 0x03 0x04 0x05 0x06 0x07 0x08 0x09 0x0a 0x0b 0x0c 0x0d 0x0e 0x0f 0x10 0x11 0x12 0x13 0x14 0x15>;
				phandle = <0xb5>;
			};
			emmc_gpio22: emmc-gpio22 {
				brcm,function = <0x07>;
				brcm,pins = <0x16 0x17 0x18 0x19 0x1a 0x1b>;
				phandle = <0x67>;
			};
			emmc_gpio34: emmc-gpio34 {
				brcm,function = <0x07>;
				brcm,pins = <0x22 0x23 0x24 0x25 0x26 0x27>;
				brcm,pull = <0x00 0x02 0x02 0x02 0x02 0x02>;
				phandle = <0x68>;
			};
			emmc_gpio48: emmc-gpio48 {
				brcm,function = <0x07>;
				brcm,pins = <0x30 0x31 0x32 0x33 0x34 0x35>;
				phandle = <0x13>;
			};
			gpclk0_gpio4: gpclk0-gpio4 {
				brcm,function = <0x04>;
				brcm,pins = <0x04>;
				phandle = <0x69>;
			};
			gpclk0_gpio49: gpclk0-gpio49 {
				phandle = <0x86>;
				pin-gpclk {
					bias-disable;
					function = "alt1";
					pins = "gpio49";
				};
			};
			gpclk1_gpio42: gpclk1-gpio42 {
				brcm,function = <0x04>;
				brcm,pins = <0x2a>;
				phandle = <0x6b>;
			};
			gpclk1_gpio44: gpclk1-gpio44 {
				brcm,function = <0x04>;
				brcm,pins = <0x2c>;
				phandle = <0x6c>;
			};
			gpclk1_gpio5: gpclk1-gpio5 {
				brcm,function = <0x04>;
				brcm,pins = <0x05>;
				phandle = <0x6a>;
			};
			gpclk1_gpio50: gpclk1-gpio50 {
				phandle = <0x87>;
				pin-gpclk {
					bias-disable;
					function = "alt1";
					pins = "gpio50";
				};
			};
			gpclk2_gpio43: gpclk2-gpio43 {
				brcm,function = <0x04>;
				brcm,pins = <0x2b>;
				brcm,pull = <0x00>;
				phandle = <0x6e>;
			};
			gpclk2_gpio51: gpclk2-gpio51 {
				phandle = <0x88>;
				pin-gpclk {
					bias-disable;
					function = "alt1";
					pins = "gpio51";
				};
			};
			gpclk2_gpio6: gpclk2-gpio6 {
				brcm,function = <0x04>;
				brcm,pins = <0x06>;
				phandle = <0x6d>;
			};
			gpioout: gpioout {
				brcm,function = <0x01>;
				brcm,pins = <0x06>;
				phandle = <0xba>;
			};
			i2c_slave_gpio8: i2c-slave-gpio8 {
				phandle = <0x93>;
				pins-i2c-slave {
					function = "alt3";
					pins = "gpio8", "gpio9", "gpio10", "gpio11";
				};
			};
			i2c0_pins: i2c0 {
				brcm,function = <0x04>;
				brcm,pins = <0x00 0x01>;
				brcm,pull = <0x02>;
				phandle = <0xbc>;
			};
			i2c0_gpio0: i2c0if-gpio0 {
				brcm,function = <0x04>;
				brcm,pins = <0x00 0x01>;
				phandle = <0x33>;
			};
			i2c0_gpio28: i2c0if-gpio28 {
				brcm,function = <0x04>;
				brcm,pins = <0x1c 0x1d>;
				phandle = <0x6f>;
			};
			i2c0_gpio44: i2c0if-gpio44 {
				brcm,function = <0x05>;
				brcm,pins = <0x2c 0x2d>;
				phandle = <0x34>;
			};
			i2c0_gpio46: i2c0if-gpio46 {
				phandle = <0x89>;
				pin-scl {
					bias-disable;
					function = "alt0";
					pins = "gpio47";
				};
				pin-sda {
					bias-pull-up;
					function = "alt0";
					pins = "gpio46";
				};
			};
			i2c1_pins: i2c1 {
				brcm,function = <0x04>;
				brcm,pins = <0x02 0x03>;
				brcm,pull = <0x02>;
				phandle = <0x15>;
			};
			i2c1_gpio2: i2c1-gpio2 {
				brcm,function = <0x04>;
				brcm,pins = <0x02 0x03>;
				phandle = <0x70>;
			};
			i2c1_gpio44: i2c1-gpio44 {
				brcm,function = <0x06>;
				brcm,pins = <0x2c 0x2d>;
				phandle = <0x71>;
			};
			i2c1_gpio46: i2c1-gpio46 {
				phandle = <0x8a>;
				pin-scl {
					bias-disable;
					function = "alt1";
					pins = "gpio47";
				};
				pin-sda {
					bias-pull-up;
					function = "alt1";
					pins = "gpio46";
				};
			};
			i2c3_pins: i2c3 {
				brcm,function = <0x02>;
				brcm,pins = <0x04 0x05>;
				brcm,pull = <0x02>;
				phandle = <0x24>;
			};
			i2c3_gpio2: i2c3-gpio2 {
				phandle = <0x8b>;
				pin-scl {
					bias-disable;
					function = "alt5";
					pins = "gpio3";
				};
				pin-sda {
					bias-pull-up;
					function = "alt5";
					pins = "gpio2";
				};
			};
			i2c3_gpio4: i2c3-gpio4 {
				phandle = <0x8c>;
				pin-scl {
					bias-disable;
					function = "alt5";
					pins = "gpio5";
				};
				pin-sda {
					bias-pull-up;
					function = "alt5";
					pins = "gpio4";
				};
			};
			i2c4_pins: i2c4 {
				brcm,function = <0x02>;
				brcm,pins = <0x08 0x09>;
				brcm,pull = <0x02>;
				phandle = <0x25>;
			};
			i2c4_gpio6: i2c4-gpio6 {
				phandle = <0x8d>;
				pin-scl {
					bias-disable;
					function = "alt5";
					pins = "gpio7";
				};
				pin-sda {
					bias-pull-up;
					function = "alt5";
					pins = "gpio6";
				};
			};
			i2c4_gpio8: i2c4-gpio8 {
				phandle = <0x8e>;
				pin-scl {
					bias-disable;
					function = "alt5";
					pins = "gpio9";
				};
				pin-sda {
					bias-pull-up;
					function = "alt5";
					pins = "gpio8";
				};
			};
			i2c5_pins: i2c5 {
				brcm,function = <0x02>;
				brcm,pins = <0x0c 0x0d>;
				brcm,pull = <0x02>;
				phandle = <0x26>;
			};
			i2c5_gpio10: i2c5-gpio10 {
				phandle = <0x8f>;
				pin-scl {
					bias-disable;
					function = "alt5";
					pins = "gpio11";
				};
				pin-sda {
					bias-pull-up;
					function = "alt5";
					pins = "gpio10";
				};
			};
			i2c5_gpio12: i2c5-gpio12 {
				phandle = <0x90>;
				pin-scl {
					bias-disable;
					function = "alt5";
					pins = "gpio13";
				};
				pin-sda {
					bias-pull-up;
					function = "alt5";
					pins = "gpio12";
				};
			};
			i2c6_pins: i2c6 {
				brcm,function = <0x02>;
				brcm,pins = <0x16 0x17>;
				brcm,pull = <0x02>;
				phandle = <0x27>;
			};
			i2c6_gpio0: i2c6-gpio0 {
				phandle = <0x91>;
				pin-scl {
					bias-disable;
					function = "alt5";
					pins = "gpio1";
				};
				pin-sda {
					bias-pull-up;
					function = "alt5";
					pins = "gpio0";
				};
			};
			i2c6_gpio22: i2c6-gpio22 {
				phandle = <0x92>;
				pin-scl {
					bias-disable;
					function = "alt5";
					pins = "gpio23";
				};
				pin-sda {
					bias-pull-up;
					function = "alt5";
					pins = "gpio22";
				};
			};
			i2s_pins: i2s {
				brcm,function = <0x04>;
				brcm,pins = <0x12 0x13 0x14 0x15>;
				phandle = <0x0d>;
			};
			jtag_gpio22: jtag-gpio22 {
				brcm,function = <0x03>;
				brcm,pins = <0x16 0x17 0x18 0x19 0x1a 0x1b>;
				phandle = <0x72>;
			};
			jtag_gpio48: jtag-gpio48 {
				phandle = <0x94>;
				pins-jtag {
					function = "alt4";
					pins = "gpio48", "gpio49", "gpio50", "gpio51", "gpio52", "gpio53";
				};
			};
			mii_gpio28: mii-gpio28 {
				phandle = <0x95>;
				pins-mii {
					function = "alt4";
					pins = "gpio28", "gpio29", "gpio30", "gpio31";
				};
			};
			mii_gpio36: mii-gpio36 {
				phandle = <0x96>;
				pins-mii {
					function = "alt5";
					pins = "gpio36", "gpio37", "gpio38", "gpio39";
				};
			};
			pcm_gpio18: pcm-gpio18 {
				brcm,function = <0x04>;
				brcm,pins = <0x12 0x13 0x14 0x15>;
				phandle = <0x73>;
			};
			pcm_gpio28: pcm-gpio28 {
				brcm,function = <0x06>;
				brcm,pins = <0x1c 0x1d 0x1e 0x1f>;
				phandle = <0x74>;
			};
			pcm_gpio50: pcm-gpio50 {
				phandle = <0x97>;
				pins-pcm {
					function = "alt2";
					pins = "gpio50", "gpio51", "gpio52", "gpio53";
				};
			};
			pwm0_0_gpio12: pwm0-0-gpio12 {
				phandle = <0x98>;
				pin-pwm {
					bias-disable;
					function = "alt0";
					pins = "gpio12";
				};
			};
			pwm0_0_gpio18: pwm0-0-gpio18 {
				phandle = <0x99>;
				pin-pwm {
					bias-disable;
					function = "alt5";
					pins = "gpio18";
				};
			};
			pwm0_0_gpio52: pwm0-0-gpio52 {
				phandle = <0x9d>;
				pin-pwm {
					bias-disable;
					function = "alt1";
					pins = "gpio52";
				};
			};
			pwm0_1_gpio13: pwm0-1-gpio13 {
				phandle = <0x9a>;
				pin-pwm {
					bias-disable;
					function = "alt0";
					pins = "gpio13";
				};
			};
			pwm0_1_gpio19: pwm0-1-gpio19 {
				phandle = <0x9b>;
				pin-pwm {
					bias-disable;
					function = "alt5";
					pins = "gpio19";
				};
			};
			pwm0_1_gpio45: pwm0-1-gpio45 {
				phandle = <0x9c>;
				pin-pwm {
					bias-disable;
					function = "alt0";
					pins = "gpio45";
				};
			};
			pwm0_1_gpio53: pwm0-1-gpio53 {
				phandle = <0x9e>;
				pin-pwm {
					bias-disable;
					function = "alt1";
					pins = "gpio53";
				};
			};
			pwm1_0_gpio40: pwm1-0-gpio40 {
				phandle = <0x28>;
				pin-pwm {
					bias-disable;
					function = "alt0";
					pins = "gpio40";
				};
			};
			pwm1_1_gpio41: pwm1-1-gpio41 {
				phandle = <0x29>;
				pin-pwm {
					bias-disable;
					function = "alt0";
					pins = "gpio41";
				};
			};
			rgmii_gpio35: rgmii-gpio35 {
				phandle = <0x9f>;
				pin-rx-ok {
					function = "alt4";
					pins = "gpio36";
				};
				pin-start-stop {
					function = "alt4";
					pins = "gpio35";
				};
			};
			rgmii_irq_gpio34: rgmii-irq-gpio34 {
				phandle = <0xa0>;
				pin-irq {
					function = "alt5";
					pins = "gpio34";
				};
			};
			rgmii_irq_gpio39: rgmii-irq-gpio39 {
				phandle = <0xa1>;
				pin-irq {
					function = "alt4";
					pins = "gpio39";
				};
			};
			rgmii_mdio_gpio28: rgmii-mdio-gpio28 {
				phandle = <0xa2>;
				pins-mdio {
					function = "alt5";
					pins = "gpio28", "gpio29";
				};
			};
			rgmii_mdio_gpio37: rgmii-mdio-gpio37 {
				phandle = <0xa3>;
				pins-mdio {
					function = "alt4";
					pins = "gpio37", "gpio38";
				};
			};
			sdhost_gpio48: sdhost-gpio48 {
				brcm,function = <0x04>;
				brcm,pins = <0x30 0x31 0x32 0x33 0x34 0x35>;
				phandle = <0x75>;
			};
			sdio_pins: sdio_pins {
				brcm,function = <0x07>;
				brcm,pins = <0x22 0x23 0x24 0x25 0x26 0x27>;
				brcm,pull = <0x00 0x02 0x02 0x02 0x02 0x02>;
				phandle = <0x31>;
			};
			spi0_gpio35: spi0-gpio35 {
				brcm,function = <0x04>;
				brcm,pins = <0x23 0x24 0x25 0x26 0x27>;
				phandle = <0x77>;
			};
			spi0_gpio46: spi0-gpio46 {
				phandle = <0xa4>;
				pins-spi {
					function = "alt2";
					pins = "gpio46", "gpio47", "gpio48", "gpio49";
				};
			};
			spi0_gpio7: spi0-gpio7 {
				brcm,function = <0x04>;
				brcm,pins = <0x07 0x08 0x09 0x0a 0x0b>;
				phandle = <0x76>;
			};
			spi0_cs_pins: spi0_cs_pins {
				brcm,function = <0x01>;
				brcm,pins = <0x08 0x07>;
				phandle = <0x0f>;
			};
			spi0_pins: spi0_pins {
				brcm,function = <0x04>;
				brcm,pins = <0x09 0x0a 0x0b>;
				phandle = <0x0e>;
			};
			spi1_gpio16: spi1-gpio16 {
				brcm,function = <0x03>;
				brcm,pins = <0x10 0x11 0x12 0x13 0x14 0x15>;
				phandle = <0x78>;
			};
			spi2_gpio40: spi2-gpio40 {
				brcm,function = <0x03>;
				brcm,pins = <0x28 0x29 0x2a 0x2b 0x2c 0x2d>;
				phandle = <0x79>;
			};
			spi2_gpio46: spi2-gpio46 {
				phandle = <0xa5>;
				pins-spi {
					function = "alt5";
					pins = "gpio46", "gpio47", "gpio48", "gpio49", "gpio50";
				};
			};
			spi3_gpio0: spi3-gpio0 {
				phandle = <0xa6>;
				pins-spi {
					function = "alt3";
					pins = "gpio0", "gpio1", "gpio2", "gpio3";
				};
			};
			spi3_cs_pins: spi3_cs_pins {
				brcm,function = <0x01>;
				brcm,pins = <0x00 0x18>;
				phandle = <0x1d>;
			};
			spi3_pins: spi3_pins {
				brcm,function = <0x07>;
				brcm,pins = <0x01 0x02 0x03>;
				phandle = <0x1c>;
			};
			spi4_gpio4: spi4-gpio4 {
				phandle = <0xa7>;
				pins-spi {
					function = "alt3";
					pins = "gpio4", "gpio5", "gpio6", "gpio7";
				};
			};
			spi4_cs_pins: spi4_cs_pins {
				brcm,function = <0x01>;
				brcm,pins = <0x04 0x19>;
				phandle = <0x1f>;
			};
			spi4_pins: spi4_pins {
				brcm,function = <0x07>;
				brcm,pins = <0x05 0x06 0x07>;
				phandle = <0x1e>;
			};
			spi5_gpio12: spi5-gpio12 {
				phandle = <0xa8>;
				pins-spi {
					function = "alt3";
					pins = "gpio12", "gpio13", "gpio14", "gpio15";
				};
			};
			spi5_cs_pins: spi5_cs_pins {
				brcm,function = <0x01>;
				brcm,pins = <0x0c 0x1a>;
				phandle = <0x21>;
			};
			spi5_pins: spi5_pins {
				brcm,function = <0x07>;
				brcm,pins = <0x0d 0x0e 0x0f>;
				phandle = <0x20>;
			};
			spi6_gpio18: spi6-gpio18 {
				phandle = <0xa9>;
				pins-spi {
					function = "alt3";
					pins = "gpio18", "gpio19", "gpio20", "gpio21";
				};
			};
			spi6_cs_pins: spi6_cs_pins {
				brcm,function = <0x01>;
				brcm,pins = <0x12 0x1b>;
				phandle = <0x23>;
			};
			spi6_pins: spi6_pins {
				brcm,function = <0x07>;
				brcm,pins = <0x13 0x14 0x15>;
				phandle = <0x22>;
			};
			uart0_ctsrts_gpio16: uart0-ctsrts-gpio16 {
				brcm,function = <0x07>;
				brcm,pins = <0x10 0x11>;
				phandle = <0x7b>;
			};
			uart0_ctsrts_gpio30: uart0-ctsrts-gpio30 {
				brcm,function = <0x07>;
				brcm,pins = <0x1e 0x1f>;
				brcm,pull = <0x02 0x00>;
				phandle = <0x7c>;
			};
			uart0_ctsrts_gpio38: uart0-ctsrts-gpio38 {
				brcm,function = <0x06>;
				brcm,pins = <0x26 0x27>;
				phandle = <0x7f>;
			};
			uart0_gpio14: uart0-gpio14 {
				brcm,function = <0x04>;
				brcm,pins = <0x0e 0x0f>;
				phandle = <0x7a>;
			};
			uart0_gpio32: uart0-gpio32 {
				brcm,function = <0x07>;
				brcm,pins = <0x20 0x21>;
				brcm,pull = <0x00 0x02>;
				phandle = <0x7d>;
			};
			uart0_gpio36: uart0-gpio36 {
				brcm,function = <0x06>;
				brcm,pins = <0x24 0x25>;
				phandle = <0x7e>;
			};
			uart0_pins: uart0_pins {
				brcm,function = <0x07>;
				brcm,pins = <0x1e 0x1f 0x20 0x21>;
				brcm,pull = <0x02 0x00 0x00 0x02>;
				phandle = <0x09>;
			};
			uart1_ctsrts_gpio16: uart1-ctsrts-gpio16 {
				brcm,function = <0x02>;
				brcm,pins = <0x10 0x11>;
				phandle = <0x81>;
			};
			uart1_ctsrts_gpio30: uart1-ctsrts-gpio30 {
				brcm,function = <0x02>;
				brcm,pins = <0x1e 0x1f>;
				phandle = <0x83>;
			};
			uart1_ctsrts_gpio42: uart1-ctsrts-gpio42 {
				brcm,function = <0x02>;
				brcm,pins = <0x2a 0x2b>;
				phandle = <0x85>;
			};
			uart1_gpio14: uart1-gpio14 {
				brcm,function = <0x02>;
				brcm,pins = <0x0e 0x0f>;
				phandle = <0x80>;
			};
			uart1_gpio32: uart1-gpio32 {
				brcm,function = <0x02>;
				brcm,pins = <0x20 0x21>;
				phandle = <0x82>;
			};
			uart1_gpio40: uart1-gpio40 {
				brcm,function = <0x02>;
				brcm,pins = <0x28 0x29>;
				phandle = <0x84>;
			};
			uart1_bt_pins: uart1_bt_pins {
				brcm,function = <0x02>;
				brcm,pins = <0x20 0x21 0x1e 0x1f>;
				brcm,pull = <0x00 0x02 0x02 0x00>;
				phandle = <0xbd>;
			};
			uart1_pins: uart1_pins {
				brcm,function;
				brcm,pins;
				brcm,pull;
				phandle = <0x12>;
			};
			uart2_ctsrts_gpio2: uart2-ctsrts-gpio2 {
				phandle = <0xab>;
				pin-cts {
					bias-pull-up;
					function = "alt4";
					pins = "gpio2";
				};
				pin-rts {
					bias-disable;
					function = "alt4";
					pins = "gpio3";
				};
			};
			uart2_gpio0: uart2-gpio0 {
				phandle = <0xaa>;
				pin-rx {
					bias-pull-up;
					function = "alt4";
					pins = "gpio1";
				};
				pin-tx {
					bias-disable;
					function = "alt4";
					pins = "gpio0";
				};
			};
			uart2_pins: uart2_pins {
				brcm,function = <0x03>;
				brcm,pins = <0x00 0x01>;
				brcm,pull = <0x00 0x02>;
				phandle = <0x18>;
			};
			uart3_ctsrts_gpio6: uart3-ctsrts-gpio6 {
				phandle = <0xad>;
				pin-cts {
					bias-pull-up;
					function = "alt4";
					pins = "gpio6";
				};
				pin-rts {
					bias-disable;
					function = "alt4";
					pins = "gpio7";
				};
			};
			uart3_gpio4: uart3-gpio4 {
				phandle = <0xac>;
				pin-rx {
					bias-pull-up;
					function = "alt4";
					pins = "gpio5";
				};
				pin-tx {
					bias-disable;
					function = "alt4";
					pins = "gpio4";
				};
			};
			uart3_pins: uart3_pins {
				brcm,function = <0x03>;
				brcm,pins = <0x04 0x05>;
				brcm,pull = <0x00 0x02>;
				phandle = <0x19>;
			};
			uart4_ctsrts_gpio10: uart4-ctsrts-gpio10 {
				phandle = <0xaf>;
				pin-cts {
					bias-pull-up;
					function = "alt4";
					pins = "gpio10";
				};
				pin-rts {
					bias-disable;
					function = "alt4";
					pins = "gpio11";
				};
			};
			uart4_gpio8: uart4-gpio8 {
				phandle = <0xae>;
				pin-rx {
					bias-pull-up;
					function = "alt4";
					pins = "gpio9";
				};
				pin-tx {
					bias-disable;
					function = "alt4";
					pins = "gpio8";
				};
			};
			uart4_pins: uart4_pins {
				brcm,function = <0x03>;
				brcm,pins = <0x08 0x09>;
				brcm,pull = <0x00 0x02>;
				phandle = <0x1a>;
			};
			uart5_ctsrts_gpio14: uart5-ctsrts-gpio14 {
				phandle = <0xb1>;
				pin-cts {
					bias-pull-up;
					function = "alt4";
					pins = "gpio14";
				};
				pin-rts {
					bias-disable;
					function = "alt4";
					pins = "gpio15";
				};
			};
			uart5_gpio12: uart5-gpio12 {
				phandle = <0xb0>;
				pin-rx {
					bias-pull-up;
					function = "alt4";
					pins = "gpio13";
				};
				pin-tx {
					bias-disable;
					function = "alt4";
					pins = "gpio12";
				};
			};
			uart5_pins: uart5_pins {
				brcm,function = <0x03>;
				brcm,pins = <0x0c 0x0d>;
				brcm,pull = <0x00 0x02>;
				phandle = <0x1b>;
			};
		};
		gpiomem {
			compatible = "brcm,bcm2835-gpiomem";
			reg = <0x7e200000 0x1000>;
		};
		hdmi0: hdmi@7ef00700 {
			clock-names = "hdmi", "bvb", "audio", "cec";
			clocks = <0x14 0x0d 0x14 0x0e 0x2b 0x00 0x2f>;
			compatible = "brcm,bcm2711-hdmi0";
			ddc = <0x2d>;
			dma-names = "audio-rx";
			dmas = <0x2e 0x41fa000a>;
			interrupt-names = "cec-tx", "cec-rx", "cec-low", "wakeup", "hpd-connected", "hpd-removed";
			interrupt-parent = <0x2c>;
			interrupts = <0x00 0x01 0x02 0x03 0x04 0x05>;
			phandle = <0x55>;
			reg = <0x7ef00700 0x300 0x7ef00300 0x200 0x7ef00f00 0x80 0x7ef00f80 0x80 0x7ef01b00 0x200 0x7ef01f00 0x400 0x7ef00200 0x80 0x7ef04300 0x100 0x7ef20000 0x100 0x7ef00100 0x30>;
			reg-names = "hdmi", "dvp", "phy", "rm", "packet", "metadata", "csc", "cec", "hd", "intr2";
			resets = <0x2b 0x00>;
			status = "disabled";
			wifi-2.4ghz-coexistence;
		};
		hdmi1: hdmi@7ef05700 {
			clock-names = "hdmi", "bvb", "audio", "cec";
			clocks = <0x14 0x0d 0x14 0x0e 0x2b 0x01 0x2f>;
			compatible = "brcm,bcm2711-hdmi1";
			ddc = <0x30>;
			dma-names = "audio-rx";
			dmas = <0x2e 0x41fa0011>;
			interrupt-names = "cec-tx", "cec-rx", "cec-low", "wakeup", "hpd-connected", "hpd-removed";
			interrupt-parent = <0x2c>;
			interrupts = <0x08 0x07 0x06 0x09 0x0a 0x0b>;
			phandle = <0x56>;
			reg = <0x7ef05700 0x300 0x7ef05300 0x200 0x7ef05f00 0x80 0x7ef05f80 0x80 0x7ef06b00 0x200 0x7ef06f00 0x400 0x7ef00280 0x80 0x7ef09300 0x100 0x7ef20000 0x100 0x7ef00100 0x30>;
			reg-names = "hdmi", "dvp", "phy", "rm", "packet", "metadata", "csc", "cec", "hd", "intr2";
			resets = <0x2b 0x01>;
			status = "disabled";
			wifi-2.4ghz-coexistence;
		};
		hvs: hvs@7e400000 {
			clocks = <0x14 0x04>;
			compatible = "brcm,bcm2711-hvs";
			interrupts = <0x00 0x61 0x04>;
			phandle = <0xc4>;
			reg = <0x7e400000 0x8000>;
			status = "disabled";
		};
		i2c0mux: i2c0mux {
			#address-cells = <0x01>;
			#size-cells = <0x00>;
			compatible = "i2c-mux-pinctrl";
			i2c-parent = <0x32>;
			phandle = <0x47>;
			pinctrl-0 = <0x33>;
			pinctrl-1 = <0x34>;
			pinctrl-names = "i2c0", "i2c_csi_dsi";
			status = "disabled";
			i2c0: i2c_vc: i2c_csi_dsi0: i2c@0 {
				#address-cells = <0x01>;
				#size-cells = <0x00>;
				phandle = <0xdd>;
				reg = <0x00>;
			};
			i2c_csi_dsi: i2c@1 {
				#address-cells = <0x01>;
				#size-cells = <0x00>;
				phandle = <0xde>;
				reg = <0x01>;
			};
		};
		i2c0if: i2c@7e205000 {
			#address-cells = <0x01>;
			#size-cells = <0x00>;
			clock-frequency = <0x186a0>;
			clocks = <0x08 0x14>;
			compatible = "brcm,bcm2711-i2c", "brcm,bcm2835-i2c";
			interrupts = <0x00 0x75 0x04>;
			phandle = <0x32>;
			reg = <0x7e205000 0x200>;
			status = "disabled";
		};
		i2c3: i2c@7e205600 {
			#address-cells = <0x01>;
			#size-cells = <0x00>;
			clocks = <0x08 0x14>;
			compatible = "brcm,bcm2711-i2c", "brcm,bcm2835-i2c";
			interrupts = <0x00 0x75 0x04>;
			phandle = <0xd0>;
			pinctrl-0 = <0x24>;
			pinctrl-names = "default";
			reg = <0x7e205600 0x200>;
			status = "disabled";
		};
		i2c4: i2c@7e205800 {
			#address-cells = <0x01>;
			#size-cells = <0x00>;
			clocks = <0x08 0x14>;
			compatible = "brcm,bcm2711-i2c", "brcm,bcm2835-i2c";
			interrupts = <0x00 0x75 0x04>;
			phandle = <0xd1>;
			pinctrl-0 = <0x25>;
			pinctrl-names = "default";
			reg = <0x7e205800 0x200>;
			status = "disabled";
		};
		i2c5: i2c@7e205a00 {
			#address-cells = <0x01>;
			#size-cells = <0x00>;
			clocks = <0x08 0x14>;
			compatible = "brcm,bcm2711-i2c", "brcm,bcm2835-i2c";
			interrupts = <0x00 0x75 0x04>;
			phandle = <0xd2>;
			pinctrl-0 = <0x26>;
			pinctrl-names = "default";
			reg = <0x7e205a00 0x200>;
			status = "disabled";
		};
		i2c6: i2c@7e205c00 {
			#address-cells = <0x01>;
			#size-cells = <0x00>;
			clocks = <0x08 0x14>;
			compatible = "brcm,bcm2711-i2c", "brcm,bcm2835-i2c";
			interrupts = <0x00 0x75 0x04>;
			phandle = <0xd3>;
			pinctrl-0 = <0x27>;
			pinctrl-names = "default";
			reg = <0x7e205c00 0x200>;
			status = "disabled";
		};
		i2c1: i2c_arm: i2c@7e804000 {
			#address-cells = <0x01>;
			#size-cells = <0x00>;
			clock-frequency = <0x186a0>;
			clocks = <0x08 0x14>;
			compatible = "brcm,bcm2711-i2c", "brcm,bcm2835-i2c";
			interrupts = <0x00 0x75 0x04>;
			phandle = <0x48>;
			pinctrl-0 = <0x15>;
			pinctrl-names = "default";
			reg = <0x7e804000 0x1000>;
			status = "disabled";
		};
		ddc0: i2c@7ef04500 {
			clock-frequency = <0x17cdc>;
			compatible = "brcm,bcm2711-hdmi-i2c";
			phandle = <0x2d>;
			reg = <0x7ef04500 0x100 0x7ef00b00 0x300>;
			reg-names = "bsc", "auto-i2c";
			status = "disabled";
		};
		ddc1: i2c@7ef09500 {
			clock-frequency = <0x17cdc>;
			compatible = "brcm,bcm2711-hdmi-i2c";
			phandle = <0x30>;
			reg = <0x7ef09500 0x100 0x7ef05b00 0x300>;
			reg-names = "bsc", "auto-i2c";
			status = "disabled";
		};
		i2s: i2s_clk_producer: i2s_clk_consumer: i2s@7e203000 {
			#sound-dai-cells = <0x00>;
			clocks = <0x08 0x1f>;
			compatible = "brcm,bcm2835-i2s";
			dma-names = "tx", "rx";
			dmas = <0x0c 0x02 0x0c 0x03>;
			phandle = <0x45>;
			pinctrl-0 = <0x0d>;
			pinctrl-names = "default";
			reg = <0x7e203000 0x24>;
			status = "disabled";
		};
		local_intc: interrupt-controller@40000000 {
			compatible = "brcm,bcm2836-l1-intc";
			phandle = <0xc6>;
			reg = <0x40000000 0x100>;
		};
		gicv2: interrupt-controller@40041000 {
			#interrupt-cells = <0x03>;
			compatible = "arm,gic-400";
			interrupt-controller;
			interrupts = <0x01 0x09 0xf04>;
			phandle = <0x01>;
			reg = <0x40041000 0x1000 0x40042000 0x2000 0x40044000 0x2000 0x40046000 0x2000>;
		};
		aon_intr: interrupt-controller@7ef00100 {
			#interrupt-cells = <0x01>;
			compatible = "brcm,bcm2711-l2-intc", "brcm,l2-intc";
			interrupt-controller;
			interrupts = <0x00 0x60 0x01>;
			phandle = <0x2c>;
			reg = <0x7ef00100 0x30>;
			status = "disabled";
		};
		vchiq: mailbox@7e00b840 {
			compatible = "brcm,bcm2711-vchiq";
			interrupts = <0x00 0x22 0x04>;
			phandle = <0xe0>;
			pinctrl-0 = <0x36>;
			pinctrl-names = "default";
			reg = <0x7e00b840 0x3c>;
		};
		mailbox: mailbox@7e00b880 {
			#mbox-cells = <0x00>;
			compatible = "brcm,bcm2835-mbox";
			interrupts = <0x00 0x21 0x04>;
			phandle = <0x35>;
			reg = <0x7e00b880 0x40>;
		};
		sdhost: mmc@7e202000 {
			brcm,overclock-50 = <0x00>;
			brcm,pio-limit = <0x01>;
			bus-width = <0x04>;
			clocks = <0x08 0x14>;
			compatible = "brcm,bcm2835-sdhost";
			dma-names = "rx-tx";
			dmas = <0x0c 0x2000000d>;
			firmware = <0x06>;
			interrupts = <0x00 0x78 0x04>;
			phandle = <0x4b>;
			reg = <0x7e202000 0x100>;
			status = "disabled";
		};
		sdhci: mmc: mmc@7e300000 {
			brcm,overclock-50 = <0x00>;
			bus-width = <0x04>;
			clocks = <0x08 0x1c>;
			compatible = "brcm,bcm2835-mmc", "brcm,bcm2835-sdhci";
			dma-names = "rx-tx";
			dmas = <0x0c 0x0b>;
			interrupts = <0x00 0x7e 0x04>;
			phandle = <0x4c>;
			pinctrl-0 = <0x13>;
			pinctrl-names = "default";
			reg = <0x7e300000 0x100>;
			status = "disabled";
		};
		mmcnr: mmcnr@7e300000 {
			brcm,overclock-50 = <0x00>;
			bus-width = <0x04>;
			clocks = <0x08 0x1c>;
			compatible = "brcm,bcm2835-mmc", "brcm,bcm2835-sdhci";
			dma-names = "rx-tx";
			dmas = <0x0c 0x0b>;
			interrupts = <0x00 0x7e 0x04>;
			non-removable;
			phandle = <0x4d>;
			pinctrl-0 = <0x31>;
			pinctrl-names = "default";
			reg = <0x7e300000 0x100>;
			status = "okay";
		};
		nvmem {
			#address-cells = <0x01>;
			#size-cells = <0x01>;
			compatible = "simple-bus";
			nvmem_cust: nvmem_cust {
				compatible = "raspberrypi,rpi-otp";
				firmware = <0x06>;
				phandle = <0x57>;
				reg = <0x01 0x08>;
				status = "okay";
			};
			nvmem_otp: nvmem_otp {
				compatible = "raspberrypi,rpi-otp";
				firmware = <0x06>;
				phandle = <0xe3>;
				reg = <0x00 0xa6>;
				status = "okay";
			};
			nvmem_priv: nvmem_priv {
				compatible = "raspberrypi,rpi-otp";
				firmware = <0x06>;
				phandle = <0x58>;
				reg = <0x03 0x08>;
				status = "okay";
			};
		};
		pixelvalve0: pixelvalve@7e206000 {
			compatible = "brcm,bcm2711-pixelvalve0";
			interrupts = <0x00 0x6d 0x04>;
			phandle = <0xd4>;
			reg = <0x7e206000 0x100>;
			status = "disabled";
		};
		pixelvalve1: pixelvalve@7e207000 {
			compatible = "brcm,bcm2711-pixelvalve1";
			interrupts = <0x00 0x6e 0x04>;
			phandle = <0xd5>;
			reg = <0x7e207000 0x100>;
			status = "disabled";
		};
		pixelvalve2: pixelvalve@7e20a000 {
			compatible = "brcm,bcm2711-pixelvalve2";
			interrupts = <0x00 0x65 0x04>;
			phandle = <0xd6>;
			reg = <0x7e20a000 0x100>;
			status = "disabled";
		};
		pixelvalve4: pixelvalve@7e216000 {
			compatible = "brcm,bcm2711-pixelvalve4";
			interrupts = <0x00 0x6e 0x04>;
			phandle = <0xd8>;
			reg = <0x7e216000 0x100>;
			status = "disabled";
		};
		pixelvalve3: pixelvalve@7ec12000 {
			compatible = "brcm,bcm2711-pixelvalve3";
			interrupts = <0x00 0x6a 0x04>;
			phandle = <0xd9>;
			reg = <0x7ec12000 0x100>;
			status = "disabled";
		};
		power: power {
			#power-domain-cells = <0x01>;
			compatible = "raspberrypi,bcm2835-power";
			firmware = <0x06>;
			phandle = <0x10>;
		};
		pwm: pwm@7e20c000 {
			#pwm-cells = <0x03>;
			assigned-clock-rates = <0x2faf080>;
			assigned-clocks = <0x08 0x1e>;
			clocks = <0x08 0x1e>;
			compatible = "brcm,bcm2835-pwm";
			phandle = <0xc3>;
			reg = <0x7e20c000 0x28>;
			status = "disabled";
		};
		pwm1: pwm@7e20c800 {
			#pwm-cells = <0x03>;
			assigned-clock-rates = <0x2faf080>;
			assigned-clocks = <0x08 0x1e>;
			clocks = <0x08 0x1e>;
			compatible = "brcm,bcm2835-pwm";
			phandle = <0xd7>;
			pinctrl-0 = <0x28 0x29>;
			pinctrl-names = "default";
			reg = <0x7e20c800 0x28>;
			status = "disabled";
		};
		random: rng@7e104000 {
			compatible = "brcm,bcm2711-rng200";
			phandle = <0x4a>;
			reg = <0x7e104000 0x28>;
			status = "okay";
		};
		uart0: serial@7e201000 {
			arm,primecell-periphid = <0x341011>;
			clock-names = "uartclk", "apb_pclk";
			clocks = <0x08 0x13 0x08 0x14>;
			compatible = "arm,pl011", "arm,primecell";
			cts-event-workaround;
			interrupts = <0x00 0x79 0x04>;
			phandle = <0x43>;
			pinctrl-0 = <0x09 0x0a>;
			pinctrl-names = "default";
			reg = <0x7e201000 0x200>;
			skip-init;
			status = "okay";
			uart-has-rtscts;
			bt: bluetooth {
				compatible = "brcm,bcm43438-bt";
				fallback-bd-address;
				local-bd-address = [a1 00 e8 32 a6 dc];
				max-speed = <0x2dc6c0>;
				phandle = <0x41>;
				shutdown-gpios = <0x0b 0x00 0x00>;
				status = "okay";
			};
		};
		uart2: serial@7e201400 {
			arm,primecell-periphid = <0x341011>;
			clock-names = "uartclk", "apb_pclk";
			clocks = <0x08 0x13 0x08 0x14>;
			compatible = "arm,pl011", "arm,primecell";
			interrupts = <0x00 0x79 0x04>;
			phandle = <0xc8>;
			pinctrl-0 = <0x18>;
			pinctrl-names = "default";
			reg = <0x7e201400 0x200>;
			status = "disabled";
		};
		uart3: serial@7e201600 {
			arm,primecell-periphid = <0x341011>;
			clock-names = "uartclk", "apb_pclk";
			clocks = <0x08 0x13 0x08 0x14>;
			compatible = "arm,pl011", "arm,primecell";
			interrupts = <0x00 0x79 0x04>;
			phandle = <0xc9>;
			pinctrl-0 = <0x19>;
			pinctrl-names = "default";
			reg = <0x7e201600 0x200>;
			status = "disabled";
		};
		uart4: serial@7e201800 {
			arm,primecell-periphid = <0x341011>;
			clock-names = "uartclk", "apb_pclk";
			clocks = <0x08 0x13 0x08 0x14>;
			compatible = "arm,pl011", "arm,primecell";
			interrupts = <0x00 0x79 0x04>;
			phandle = <0xca>;
			pinctrl-0 = <0x1a>;
			pinctrl-names = "default";
			reg = <0x7e201800 0x200>;
			status = "disabled";
		};
		uart5: serial@7e201a00 {
			arm,primecell-periphid = <0x341011>;
			clock-names = "uartclk", "apb_pclk";
			clocks = <0x08 0x13 0x08 0x14>;
			compatible = "arm,pl011", "arm,primecell";
			interrupts = <0x00 0x79 0x04>;
			phandle = <0xcb>;
			pinctrl-0 = <0x1b>;
			pinctrl-names = "default";
			reg = <0x7e201a00 0x200>;
			status = "disabled";
		};
		uart1: serial@7e215040 {
			clocks = <0x11 0x00>;
			compatible = "brcm,bcm2835-aux-uart";
			interrupts = <0x00 0x5d 0x04>;
			phandle = <0x44>;
			pinctrl-0 = <0x12>;
			pinctrl-names = "default";
			reg = <0x7e215040 0x40>;
			skip-init;
			status = "okay";
			minibt: bluetooth {
				compatible = "brcm,bcm43438-bt";
				fallback-bd-address;
				local-bd-address = [00 00 00 00 00 00];
				max-speed = <0x38400>;
				phandle = <0x42>;
				shutdown-gpios = <0x0b 0x00 0x00>;
				status = "disabled";
			};
		};
		smi: smi@7e600000 {
			assigned-clock-rates = <0x7735940>;
			assigned-clocks = <0x08 0x2a>;
			clocks = <0x08 0x2a>;
			compatible = "brcm,bcm2835-smi";
			dma-names = "rx-tx";
			dmas = <0x0c 0x04>;
			interrupts = <0x00 0x70 0x04>;
			phandle = <0xdc>;
			reg = <0x7e600000 0x100>;
			status = "disabled";
		};
		sound: sound {
			phandle = <0xe2>;
			status = "disabled";
		};
		spi: spi0: spi@7e204000 {
			#address-cells = <0x01>;
			#size-cells = <0x00>;
			clocks = <0x08 0x14>;
			compatible = "brcm,bcm2835-spi";
			cs-gpios = <0x07 0x08 0x01 0x07 0x07 0x01>;
			dma-names = "tx", "rx";
			dmas = <0x0c 0x06 0x0c 0x07>;
			interrupts = <0x00 0x76 0x04>;
			phandle = <0x46>;
			pinctrl-0 = <0x0e 0x0f>;
			pinctrl-names = "default";
			reg = <0x7e204000 0x200>;
			status = "disabled";
			spidev0: spidev@0 {
				#address-cells = <0x01>;
				#size-cells = <0x00>;
				compatible = "spidev";
				phandle = <0xbe>;
				reg = <0x00>;
				spi-max-frequency = <0x7735940>;
			};
			spidev1: spidev@1 {
				#address-cells = <0x01>;
				#size-cells = <0x00>;
				compatible = "spidev";
				phandle = <0xbf>;
				reg = <0x01>;
				spi-max-frequency = <0x7735940>;
			};
		};
		spi3: spi@7e204600 {
			#address-cells = <0x01>;
			#size-cells = <0x00>;
			clocks = <0x08 0x14>;
			compatible = "brcm,bcm2835-spi";
			interrupts = <0x00 0x76 0x04>;
			phandle = <0xcc>;
			pinctrl-0 = <0x1c 0x1d>;
			pinctrl-names = "default";
			reg = <0x7e204600 0x200>;
			status = "disabled";
		};
		spi4: spi@7e204800 {
			#address-cells = <0x01>;
			#size-cells = <0x00>;
			clocks = <0x08 0x14>;
			compatible = "brcm,bcm2835-spi";
			interrupts = <0x00 0x76 0x04>;
			phandle = <0xcd>;
			pinctrl-0 = <0x1e 0x1f>;
			pinctrl-names = "default";
			reg = <0x7e204800 0x200>;
			status = "disabled";
		};
		spi5: spi@7e204a00 {
			#address-cells = <0x01>;
			#size-cells = <0x00>;
			clocks = <0x08 0x14>;
			compatible = "brcm,bcm2835-spi";
			interrupts = <0x00 0x76 0x04>;
			phandle = <0xce>;
			pinctrl-0 = <0x20 0x21>;
			pinctrl-names = "default";
			reg = <0x7e204a00 0x200>;
			status = "disabled";
		};
		spi6: spi@7e204c00 {
			#address-cells = <0x01>;
			#size-cells = <0x00>;
			clocks = <0x08 0x14>;
			compatible = "brcm,bcm2835-spi";
			interrupts = <0x00 0x76 0x04>;
			phandle = <0xcf>;
			pinctrl-0 = <0x22 0x23>;
			pinctrl-names = "default";
			reg = <0x7e204c00 0x200>;
			status = "disabled";
		};
		spi1: spi@7e215080 {
			#address-cells = <0x01>;
			#size-cells = <0x00>;
			clocks = <0x11 0x01>;
			compatible = "brcm,bcm2835-aux-spi";
			interrupts = <0x00 0x5d 0x04>;
			phandle = <0xc1>;
			reg = <0x7e215080 0x40>;
			status = "disabled";
		};
		spi2: spi@7e2150c0 {
			#address-cells = <0x01>;
			#size-cells = <0x00>;
			clocks = <0x11 0x02>;
			compatible = "brcm,bcm2835-aux-spi";
			interrupts = <0x00 0x5d 0x04>;
			phandle = <0xc2>;
			reg = <0x7e2150c0 0x40>;
			status = "disabled";
		};
		system_timer: timer@7e003000 {
			clock-frequency = <0xf4240>;
			compatible = "brcm,bcm2835-system-timer";
			interrupts = <0x00 0x40 0x04 0x00 0x41 0x04 0x00 0x42 0x04 0x00 0x43 0x04>;
			phandle = <0x64>;
			reg = <0x7e003000 0x1000>;
			status = "disabled";
		};
		txp: txp@7e004000 {
			compatible = "brcm,bcm2835-txp";
			interrupts = <0x00 0x4b 0x04>;
			phandle = <0x65>;
			reg = <0x7e004000 0x20>;
			status = "disabled";
		};
		usb: usb@7e980000 {
			#address-cells = <0x01>;
			#size-cells = <0x00>;
			clock-names = "otg";
			clocks = <0x16>;
			compatible = "brcm,bcm2708-usb";
			interrupt-names = "usb", "soft";
			interrupts = <0x00 0x49 0x04 0x00 0x28 0x04>;
			phandle = <0xc5>;
			phy-names = "usb2-phy";
			phys = <0x17>;
			power-domains = <0x10 0x06>;
			reg = <0x7e980000 0x10000 0x7e00b200 0x200>;
			status = "disabled";
		};
		vec: vec@7ec13000 {
			clocks = <0x14 0x0f>;
			compatible = "brcm,bcm2711-vec";
			interrupts = <0x00 0x7b 0x04>;
			phandle = <0xda>;
			power-domains = <0x10 0x07>;
			reg = <0x7ec13000 0x1000>;
			status = "disabled";
		};
		pm: watchdog: watchdog@7e100000 {
			#power-domain-cells = <0x01>;
			#reset-cells = <0x01>;
			clock-names = "v3d", "peri_image", "h264", "isp";
			clocks = <0x08 0x15 0x08 0x1d 0x08 0x17 0x08 0x16>;
			compatible = "brcm,bcm2711-pm", "brcm,bcm2835-pm-wdt";
			phandle = <0x49>;
			reg = <0x7e100000 0x114 0x7e00a000 0x24 0x7ec11000 0x20>;
			reg-names = "pm", "asb", "rpivid_asb";
			system-power-controller;
		};
	};
	system {
		linux,revision = <0xc03111>;
		linux,serial = <0x10000000 0x3de9072a>;
	};
	thermal-zones {
		cpu_thermal: cpu-thermal {
			coefficients = <0xfffffe19 0x641b8>;
			phandle = <0x60>;
			polling-delay = <0x3e8>;
			polling-delay-passive = <0x00>;
			thermal-sensors = <0x02>;
			cooling_maps: cooling-maps {
				phandle = <0x62>;
			};
			thermal_trips: trips {
				phandle = <0x61>;
				cpu-crit {
					hysteresis = <0x00>;
					temperature = <0x1adb0>;
					type = "critical";
				};
			};
		};
	};
	timer {
		compatible = "arm,armv8-timer";
		interrupts = <0x01 0x0d 0xf08 0x01 0x0e 0xf08 0x01 0x0b 0xf08 0x01 0x0a 0xf08>;
	};
	v3dbus: v3dbus {
		#address-cells = <0x01>;
		#size-cells = <0x02>;
		compatible = "simple-bus";
		dma-ranges = <0x00 0x00 0x00 0x04 0x00>;
		phandle = <0xf1>;
		ranges = <0x7c500000 0x00 0xfc500000 0x00 0x3300000 0x40000000 0x00 0xff800000 0x00 0x800000>;
		v3d: v3d@7ec04000 {
			clocks = <0x14 0x05>;
			clocks-names = "v3d";
			compatible = "brcm,2711-v3d";
			interrupts = <0x00 0x4a 0x04>;
			phandle = <0xf2>;
			power-domains = <0x49 0x01>;
			reg = <0x7ec00000 0x00 0x4000 0x7ec04000 0x00 0x4000>;
			reg-names = "hub", "core0";
			resets = <0x49 0x00>;
			status = "disabled";
		};
	};
	zone_dma {
		#address-cells = <0x01>;
		#size-cells = <0x01>;
		dma-ranges = <0x00 0x00 0x00 0x40000000>;
	};
};
